AUTOSAR XML (schema 4-2-1)
package /MICROSAR/Dcm_swc
  4 x mode declaration group, all with category=EXPLICIT_ORDER:
    DcmControlDtcSetting: initial-mode=ENABLEDTCSETTING, on-transition-value=2
      mode ENABLEDTCSETTING: value=0
      mode DISABLEDTCSETTING: value=1
    DcmEcuReset: initial-mode=NONE, on-transition-value=7
      7 x mode:
        NONE: value=0
        HARD: value=1
        KEYONOFF: value=2
        SOFT: value=3
        JUMPTOBOOTLOADER: value=4
        JUMPTOSYSSUPPLIERBOOTLOADER: value=5
        EXECUTE: value=6
    DcmDiagnosticSessionControl: initial-mode=DEFAULT_SESSION, on-transition-value=255
      mode DEFAULT_SESSION: value=1
      mode EXTENDED_SESSION: value=3
    DcmCommunicationControl: initial-mode=DCM_ENABLE_RX_TX_NORM, on-transition-value=12
      12 x mode:
        DCM_ENABLE_RX_TX_NORM: value=0
        DCM_ENABLE_RX_DISABLE_TX_NORM: value=1
        DCM_DISABLE_RX_ENABLE_TX_NORM: value=2
        DCM_DISABLE_RX_TX_NORMAL: value=3
        DCM_ENABLE_RX_TX_NM: value=4
        DCM_ENABLE_RX_DISABLE_TX_NM: value=5
        DCM_DISABLE_RX_ENABLE_TX_NM: value=6
        DCM_DISABLE_RX_TX_NM: value=7
        DCM_ENABLE_RX_TX_NORM_NM: value=8
        DCM_ENABLE_RX_DISABLE_TX_NORM_NM: value=9
        DCM_DISABLE_RX_ENABLE_TX_NORM_NM: value=10
        DCM_DISABLE_RX_TX_NORM_NM: value=11
  data type mapping set DcmMappingSet  # Contains mapping for ModeDeclarationGroups which are provided by Dcm.
    mode-request-type-maps:
      implementation-data-type=Dcm_ControlDtcSettingType, mode-group=DcmControlDtcSetting
      implementation-data-type=Dcm_EcuResetType, mode-group=DcmEcuReset
      implementation-data-type=Dcm_DiagnosticSessionControlType, mode-group=DcmDiagnosticSessionControl
      implementation-data-type=Dcm_CommunicationModeType, mode-group=DcmCommunicationControl
package /MICROSAR/Dcm_swc/DataTypes
  22 x impl type:
    Dcm_ConfirmationStatusType: compu {0=DCM_RES_POS_OK, 1=DCM_RES_POS_NOT_OK, 2=DCM_RES_NEG_OK, 3=DCM_RES_NEG_NOT_OK}, range raw 0..3, implementation-data-type=uint8
    Dcm_OpStatusType: compu {0=DCM_INITIAL, 1=DCM_PENDING, 2=DCM_CANCEL, 3=DCM_FORCE_RCRRP_OK, 64=DCM_FORCE_RCRRP_NOT_OK}, range raw 0..64, implementation-data-type=uint8
    Dcm_NegativeResponseCodeType:
      compu {0=DCM_E_POSITIVERESPONSE, 16=DCM_E_GENERALREJECT, 17=DCM_E_SERVICENOTSUPPORTED, 18=DCM_E_SUBFUNCTIONNOTSUPPORTED, 19=DCM_E_INCORRECTMESSAGELENGTHORINVALIDFORMAT, 20=DCM_E_RESPONSETOOLONG, 33=DCM_E_BUSYREPEATREQUEST, 34=DCM_E_CONDITIONSNOTCORRECT, 36=DCM_E_REQUESTSEQUENCEERROR, 37=DCM_E_NORESPONSEFROMSUBNETCOMPONENT, 38=DCM_E_FAILUREPREVENTSEXECUTIONOFREQUESTEDACTION, 49=DCM_E_REQUESTOUTOFRANGE, 51=DCM_E_SECURITYACCESSDENIED, 53=DCM_E_INVALIDKEY, 54=DCM_E_EXCEEDNUMBEROFATTEMPTS, 55=DCM_E_REQUIREDTIMEDELAYNOTEXPIRED, 112=DCM_E_UPLOADDOWNLOADNOTACCEPTED, 113=DCM_E_TRANSFERDATASUSPENDED, 114=DCM_E_GENERALPROGRAMMINGFAILURE, 115=DCM_E_WRONGBLOCKSEQUENCECOUNTER, 120=DCM_E_REQUESTCORRECTLYRECEIVEDRESPONSEPENDING, 126=DCM_E_SUBFUNCTIONNOTSUPPORTEDINACTIVESESSION, 127=DCM_E_SERVICENOTSUPPORTEDINACTIVESESSION, 129=DCM_E_RPMTOOHIGH, 130=DCM_E_RPMTOOLOW, 131=DCM_E_ENGINEISRUNNING, 132=DCM_E_ENGINEISNOTRUNNING, 133=DCM_E_ENGINERUNTIMETOOLOW, 134=DCM_E_TEMPERATURETOOHIGH, 135=DCM_E_TEMPERATURETOOLOW, 136=DCM_E_VEHICLESPEEDTOOHIGH, 137=DCM_E_VEHICLESPEEDTOOLOW, 138=DCM_E_THROTTLE_PEDALTOOHIGH, 139=DCM_E_THROTTLE_PEDALTOOLOW, 140=DCM_E_TRANSMISSIONRANGENOTINNEUTRAL, 141=DCM_E_TRANSMISSIONRANGENOTINGEAR, 143=DCM_E_BRAKESWITCH_NOTCLOSED, 144=DCM_E_SHIFTERLEVERNOTINPARK, 145=DCM_E_TORQUECONVERTERCLUTCHLOCKED, 146=DCM_E_VOLTAGETOOHIGH, 147=DCM_E_VOLTAGETOOLOW, 240..249=DCM_E_VMSCNC_0..DCM_E_VMSCNC_9, 250=DCM_E_VMSCNC_A, 251=DCM_E_VMSCNC_B, 252=DCM_E_VMSCNC_C, 253=DCM_E_VMSCNC_D, 254=DCM_E_VMSCNC_E}
      range raw 0..254
      implementation-data-type=uint8
    Dcm_ProtocolType: compu {0=DCM_OBD_ON_CAN, 1=DCM_OBD_ON_FLEXRAY, 2=DCM_OBD_ON_IP, 3=DCM_UDS_ON_CAN, 4=DCM_UDS_ON_FLEXRAY, 5=DCM_UDS_ON_IP, 12=DCM_NO_ACTIVE_PROTOCOL, 240..254=DCM_SUPPLIER_1..DCM_SUPPLIER_15}, range raw 0..254, implementation-data-type=uint8
    Dcm_RequestKindType: compu {0=DCM_REQ_KIND_NONE, 1=DCM_REQ_KIND_EXTERNAL, 2=DCM_REQ_KIND_ROE}, range raw 0..2, implementation-data-type=uint8
    Dcm_SecLevelType: compu {0=DCM_SEC_LEV_LOCKED, 1=DCM_SEC_LEV_L1}, range raw 0..1, implementation-data-type=uint8
    Dcm_SesCtrlType: compu {1=DCM_DEFAULT_SESSION, 3=DCM_EXTENDED_DIAGNOSTIC_SESSION}, range raw 0..3, implementation-data-type=uint8
    Dcm_ControlDtcSettingType: compu {0=DCM_ENUM_ENABLEDTCSETTING, 1=DCM_ENUM_DISABLEDTCSETTING}, range raw 0..255, implementation-data-type=uint8
    Dcm_EcuResetType: compu {0=DCM_ENUM_NONE, 1=DCM_ENUM_HARD, 2=DCM_ENUM_KEYONOFF, 3=DCM_ENUM_SOFT, 4=DCM_ENUM_JUMPTOBOOTLOADER, 5=DCM_ENUM_JUMPTOSYSSUPPLIERBOOTLOADER, 6=DCM_ENUM_EXECUTE}, range raw 0..255, implementation-data-type=uint8
    Dcm_DiagnosticSessionControlType: compu {1=DCM_ENUM_DEFAULT_SESSION, 3=DCM_ENUM_EXTENDED_SESSION}, range raw 0..255, implementation-data-type=uint8
    Dcm_CommunicationModeType:
      compu {0=DCM_ENABLE_RX_TX_NORM, 1=DCM_ENABLE_RX_DISABLE_TX_NORM, 2=DCM_DISABLE_RX_ENABLE_TX_NORM, 3=DCM_DISABLE_RX_TX_NORMAL, 4=DCM_ENABLE_RX_TX_NM, 5=DCM_ENABLE_RX_DISABLE_TX_NM, 6=DCM_DISABLE_RX_ENABLE_TX_NM, 7=DCM_DISABLE_RX_TX_NM, 8=DCM_ENABLE_RX_TX_NORM_NM, 9=DCM_ENABLE_RX_DISABLE_TX_NORM_NM, 10=DCM_DISABLE_RX_ENABLE_TX_NORM_NM, 11=DCM_DISABLE_RX_TX_NORM_NM}
      range raw 0..255
      implementation-data-type=uint8
    Dcm_Data4ByteType: category=ARRAY, sw-calibration-access=READ-ONLY
      element Dcm_Data4ByteTypeElement: array-size=4, array-size-semantics=FIXED-SIZE, implementation-data-type=uint8
    Dcm_Data2ByteType: category=ARRAY, sw-calibration-access=READ-ONLY
      element Dcm_Data2ByteTypeElement: array-size=2, array-size-semantics=FIXED-SIZE, implementation-data-type=uint8
    Dcm_Data1ByteType: category=ARRAY, sw-calibration-access=READ-ONLY
      element Dcm_Data1ByteTypeElement: array-size=1, array-size-semantics=FIXED-SIZE, implementation-data-type=uint8
    Dcm_Data16ByteType: category=ARRAY, sw-calibration-access=READ-ONLY
      element Dcm_Data16ByteTypeElement: array-size=16, array-size-semantics=FIXED-SIZE, implementation-data-type=uint8
    Dcm_Data17ByteType: category=ARRAY, sw-calibration-access=READ-ONLY
      element Dcm_Data17ByteTypeElement: array-size=17, array-size-semantics=FIXED-SIZE, implementation-data-type=uint8
    Dcm_Data50ByteType: category=ARRAY, sw-calibration-access=READ-ONLY
      element Dcm_Data50ByteTypeElement: array-size=50, array-size-semantics=FIXED-SIZE, implementation-data-type=uint8
    Dcm_Data28ByteType: category=ARRAY, sw-calibration-access=READ-ONLY
      element Dcm_Data28ByteTypeElement: array-size=28, array-size-semantics=FIXED-SIZE, implementation-data-type=uint8
    Dcm_Data10ByteType: category=ARRAY, sw-calibration-access=READ-ONLY
      element Dcm_Data10ByteTypeElement: array-size=10, array-size-semantics=FIXED-SIZE, implementation-data-type=uint8
    Dcm_Data6ByteType: category=ARRAY, sw-calibration-access=READ-ONLY
      element Dcm_Data6ByteTypeElement: array-size=6, array-size-semantics=FIXED-SIZE, implementation-data-type=uint8
    Dcm_Data3ByteType: category=ARRAY, sw-calibration-access=READ-ONLY
      element Dcm_Data3ByteTypeElement: array-size=3, array-size-semantics=FIXED-SIZE, implementation-data-type=uint8
    Dcm_Data15ByteType: category=ARRAY, sw-calibration-access=READ-ONLY
      element Dcm_Data15ByteTypeElement: array-size=15, array-size-semantics=FIXED-SIZE, implementation-data-type=uint8
package /MICROSAR/Dcm_swc/Interfaces
  mode switch interface DcmControlDtcSetting: is-service=true, service-kind=DIAGNOSTIC-COMMUNICATION-MANAGER
    mode group DcmControlDtcSetting: type=DcmControlDtcSetting
  mode switch interface DcmEcuReset: is-service=true, service-kind=DIAGNOSTIC-COMMUNICATION-MANAGER
    mode group DcmEcuReset: type=DcmEcuReset
  mode switch interface DcmDiagnosticSessionControl: is-service=true, service-kind=DIAGNOSTIC-COMMUNICATION-MANAGER
    mode group DcmDiagnosticSessionControl: type=DcmDiagnosticSessionControl
  106 x client server interface, all with is-service=true, service-kind=DIAGNOSTIC-COMMUNICATION-MANAGER:
    DCMServices
      6 x operation:
        GetActiveProtocol: possible-error=E_OK
          arg ActiveProtocol: type=Dcm_ProtocolType, direction=OUT
        GetSesCtrlType: possible-error=E_OK
          arg SesCtrlType: type=Dcm_SesCtrlType, direction=OUT
        ResetToDefaultSession: possible-error=E_OK
        GetSecurityLevel: possible-error=E_OK
          arg SecLevel: type=Dcm_SecLevelType, direction=OUT
        SetActiveDiagnostic: possible-error=E_OK
          arg active: type=boolean, direction=IN
        GetRequestKind: possible-error=DCMServices/E_NOT_OK
          arg TesterSourceAddress: type=uint16, direction=IN
          arg RequestKind: type=Dcm_RequestKindType, direction=OUT
      error E_OK: error-code=0
      error E_NOT_OK: error-code=1
    SecurityAccess_UnlockedL1
      operation GetSeed: possible-error=[SecurityAccess_UnlockedL1/E_NOT_OK, SecurityAccess_UnlockedL1/DCM_E_PENDING]
        arg OpStatus: type=Dcm_OpStatusType, direction=IN
        arg Seed: type=Dcm_Data4ByteType, direction=OUT
        arg ErrorCode: type=Dcm_NegativeResponseCodeType, direction=OUT
      operation CompareKey: possible-error=[SecurityAccess_UnlockedL1/E_NOT_OK, SecurityAccess_UnlockedL1/DCM_E_PENDING, DCM_E_COMPARE_KEY_FAILED]
        arg Key: type=Dcm_Data4ByteType, direction=IN
        arg OpStatus: type=Dcm_OpStatusType, direction=IN
        arg ErrorCode: type=Dcm_NegativeResponseCodeType, direction=OUT
      error E_NOT_OK: error-code=1
      error DCM_E_PENDING: error-code=10
      error DCM_E_COMPARE_KEY_FAILED: error-code=11
    RoutineServices_HUT_self_check
      operation Start: possible-error=[RoutineServices_HUT_self_check/E_NOT_OK, RoutineServices_HUT_self_check/DCM_E_PENDING, DCM_E_FORCE_RCRRP]
        arg OpStatus: type=Dcm_OpStatusType, direction=IN
        arg ErrorCode: type=Dcm_NegativeResponseCodeType, direction=OUT
      operation Stop: possible-error=[RoutineServices_HUT_self_check/E_NOT_OK, RoutineServices_HUT_self_check/DCM_E_PENDING, DCM_E_FORCE_RCRRP]
        arg OpStatus: type=Dcm_OpStatusType, direction=IN
        arg ErrorCode: type=Dcm_NegativeResponseCodeType, direction=OUT
      operation RequestResults: possible-error=[RoutineServices_HUT_self_check/E_NOT_OK, RoutineServices_HUT_self_check/DCM_E_PENDING, DCM_E_FORCE_RCRRP]
        arg OpStatus: type=Dcm_OpStatusType, direction=IN
        arg ErrorCode: type=Dcm_NegativeResponseCodeType, direction=OUT
      error E_NOT_OK: error-code=1
      error DCM_E_PENDING: error-code=10
      error DCM_E_FORCE_RCRRP: error-code=12
    DataServices_Vehicle_Speed_D001_Vehicle_Speed
      operation ReadData: possible-error=[DataServices_Vehicle_Speed_D001_Vehicle_Speed/E_NOT_OK, DataServices_Vehicle_Speed_D001_Vehicle_Speed/DCM_E_PENDING]
        arg OpStatus: type=Dcm_OpStatusType, direction=IN
        arg Data: type=Dcm_Data2ByteType, direction=OUT
      operation ConditionCheckRead: possible-error=[DataServices_Vehicle_Speed_D001_Vehicle_Speed/E_NOT_OK, DataServices_Vehicle_Speed_D001_Vehicle_Speed/DCM_E_PENDING]
        arg OpStatus: type=Dcm_OpStatusType, direction=IN
        arg ErrorCode: type=Dcm_NegativeResponseCodeType, direction=OUT
      error E_NOT_OK: error-code=1
      error DCM_E_PENDING: error-code=10
    DataServices_Telematics_Module_Status_E01A_Telematics_Module_Status
      operation ReadData: possible-error=[DataServices_Telematics_Module_Status_E01A_Telematics_Module_Status/E_NOT_OK, DataServices_Telematics_Module_Status_E01A_Telematics_Module_Status/DCM_E_PENDING]
        arg OpStatus: type=Dcm_OpStatusType, direction=IN
        arg Data: type=Dcm_Data1ByteType, direction=OUT
      operation ConditionCheckRead: possible-error=[DataServices_Telematics_Module_Status_E01A_Telematics_Module_Status/E_NOT_OK, DataServices_Telematics_Module_Status_E01A_Telematics_Module_Status/DCM_E_PENDING]
        arg OpStatus: type=Dcm_OpStatusType, direction=IN
        arg ErrorCode: type=Dcm_NegativeResponseCodeType, direction=OUT
      error E_NOT_OK: error-code=1
      error DCM_E_PENDING: error-code=10
    DataServices_Wi_Fi_Module_Status_E013_Wi_Fi_Module_Status
      operation ReadData: possible-error=[DataServices_Wi_Fi_Module_Status_E013_Wi_Fi_Module_Status/E_NOT_OK, DataServices_Wi_Fi_Module_Status_E013_Wi_Fi_Module_Status/DCM_E_PENDING]
        arg OpStatus: type=Dcm_OpStatusType, direction=IN
        arg Data: type=Dcm_Data1ByteType, direction=OUT
      operation ConditionCheckRead: possible-error=[DataServices_Wi_Fi_Module_Status_E013_Wi_Fi_Module_Status/E_NOT_OK, DataServices_Wi_Fi_Module_Status_E013_Wi_Fi_Module_Status/DCM_E_PENDING]
        arg OpStatus: type=Dcm_OpStatusType, direction=IN
        arg ErrorCode: type=Dcm_NegativeResponseCodeType, direction=OUT
      error E_NOT_OK: error-code=1
      error DCM_E_PENDING: error-code=10
    DataServices_BT_firmware_version_E009_BT_firmware_version
      operation ReadData: possible-error=[DataServices_BT_firmware_version_E009_BT_firmware_version/E_NOT_OK, DataServices_BT_firmware_version_E009_BT_firmware_version/DCM_E_PENDING]
        arg OpStatus: type=Dcm_OpStatusType, direction=IN
        arg Data: type=Dcm_Data16ByteType, direction=OUT
      operation ConditionCheckRead: possible-error=[DataServices_BT_firmware_version_E009_BT_firmware_version/E_NOT_OK, DataServices_BT_firmware_version_E009_BT_firmware_version/DCM_E_PENDING]
        arg OpStatus: type=Dcm_OpStatusType, direction=IN
        arg ErrorCode: type=Dcm_NegativeResponseCodeType, direction=OUT
      error E_NOT_OK: error-code=1
      error DCM_E_PENDING: error-code=10
    DataServices_BT_active_profile_list_E008_BT_active_profile_list
      operation ReadData: possible-error=[DataServices_BT_active_profile_list_E008_BT_active_profile_list/E_NOT_OK, DataServices_BT_active_profile_list_E008_BT_active_profile_list/DCM_E_PENDING]
        arg OpStatus: type=Dcm_OpStatusType, direction=IN
        arg Data: type=Dcm_Data1ByteType, direction=OUT
      operation ConditionCheckRead: possible-error=[DataServices_BT_active_profile_list_E008_BT_active_profile_list/E_NOT_OK, DataServices_BT_active_profile_list_E008_BT_active_profile_list/DCM_E_PENDING]
        arg OpStatus: type=Dcm_OpStatusType, direction=IN
        arg ErrorCode: type=Dcm_NegativeResponseCodeType, direction=OUT
      error E_NOT_OK: error-code=1
      error DCM_E_PENDING: error-code=10
    DataServices_Vehicle_Identification_Number_F190_VIN
      operation ReadData: possible-error=[DataServices_Vehicle_Identification_Number_F190_VIN/E_NOT_OK, DataServices_Vehicle_Identification_Number_F190_VIN/DCM_E_PENDING]
        arg OpStatus: type=Dcm_OpStatusType, direction=IN
        arg Data: type=Dcm_Data17ByteType, direction=OUT
      operation ConditionCheckRead: possible-error=[DataServices_Vehicle_Identification_Number_F190_VIN/E_NOT_OK, DataServices_Vehicle_Identification_Number_F190_VIN/DCM_E_PENDING]
        arg OpStatus: type=Dcm_OpStatusType, direction=IN
        arg ErrorCode: type=Dcm_NegativeResponseCodeType, direction=OUT
      operation WriteData: possible-error=[DataServices_Vehicle_Identification_Number_F190_VIN/E_NOT_OK, DataServices_Vehicle_Identification_Number_F190_VIN/DCM_E_PENDING]
        arg Data: type=Dcm_Data17ByteType, direction=IN
        arg OpStatus: type=Dcm_OpStatusType, direction=IN
        arg ErrorCode: type=Dcm_NegativeResponseCodeType, direction=OUT
      error E_NOT_OK: error-code=1
      error DCM_E_PENDING: error-code=10
    DataServices_AME_Read_SW_and_HW_Version_FD04_CombinedDataElement
      operation ReadData: possible-error=[DataServices_AME_Read_SW_and_HW_Version_FD04_CombinedDataElement/E_NOT_OK, DataServices_AME_Read_SW_and_HW_Version_FD04_CombinedDataElement/DCM_E_PENDING]
        arg OpStatus: type=Dcm_OpStatusType, direction=IN
        arg Data: type=Dcm_Data50ByteType, direction=OUT
      operation ReadDataLength: possible-error=[DataServices_AME_Read_SW_and_HW_Version_FD04_CombinedDataElement/E_NOT_OK, DataServices_AME_Read_SW_and_HW_Version_FD04_CombinedDataElement/DCM_E_PENDING]
        arg OpStatus: type=Dcm_OpStatusType, direction=IN
        arg DataLength: type=uint16, direction=OUT
      operation ConditionCheckRead: possible-error=[DataServices_AME_Read_SW_and_HW_Version_FD04_CombinedDataElement/E_NOT_OK, DataServices_AME_Read_SW_and_HW_Version_FD04_CombinedDataElement/DCM_E_PENDING]
        arg OpStatus: type=Dcm_OpStatusType, direction=IN
        arg ErrorCode: type=Dcm_NegativeResponseCodeType, direction=OUT
      error E_NOT_OK: error-code=1
      error DCM_E_PENDING: error-code=10
    DataServices_AME_Skip_welcome_confirm_FD20_Reserved_Byte
      operation WriteData: possible-error=[DataServices_AME_Skip_welcome_confirm_FD20_Reserved_Byte/E_NOT_OK, DataServices_AME_Skip_welcome_confirm_FD20_Reserved_Byte/DCM_E_PENDING]
        arg Data: type=Dcm_Data1ByteType, direction=IN
        arg OpStatus: type=Dcm_OpStatusType, direction=IN
        arg ErrorCode: type=Dcm_NegativeResponseCodeType, direction=OUT
      error E_NOT_OK: error-code=1
      error DCM_E_PENDING: error-code=10
    DataServices_Select_Speaker_Test_Tone_FD34_Select_tone
      operation WriteData: possible-error=[DataServices_Select_Speaker_Test_Tone_FD34_Select_tone/E_NOT_OK, DataServices_Select_Speaker_Test_Tone_FD34_Select_tone/DCM_E_PENDING]
        arg Data: type=Dcm_Data1ByteType, direction=IN
        arg OpStatus: type=Dcm_OpStatusType, direction=IN
        arg ErrorCode: type=Dcm_NegativeResponseCodeType, direction=OUT
      error E_NOT_OK: error-code=1
      error DCM_E_PENDING: error-code=10
    DataServices_AME_Read_GPS_Info_FD72_Number_of_used_satellite
      operation ReadData: possible-error=[DataServices_AME_Read_GPS_Info_FD72_Number_of_used_satellite/E_NOT_OK, DataServices_AME_Read_GPS_Info_FD72_Number_of_used_satellite/DCM_E_PENDING]
        arg OpStatus: type=Dcm_OpStatusType, direction=IN
        arg Data: type=Dcm_Data1ByteType, direction=OUT
      operation ConditionCheckRead: possible-error=[DataServices_AME_Read_GPS_Info_FD72_Number_of_used_satellite/E_NOT_OK, DataServices_AME_Read_GPS_Info_FD72_Number_of_used_satellite/DCM_E_PENDING]
        arg OpStatus: type=Dcm_OpStatusType, direction=IN
        arg ErrorCode: type=Dcm_NegativeResponseCodeType, direction=OUT
      error E_NOT_OK: error-code=1
      error DCM_E_PENDING: error-code=10
    DataServices_AME_Read_GPS_Info_FD72_Number_of_visible_staellite
      operation ReadData: possible-error=[DataServices_AME_Read_GPS_Info_FD72_Number_of_visible_staellite/E_NOT_OK, DataServices_AME_Read_GPS_Info_FD72_Number_of_visible_staellite/DCM_E_PENDING]
        arg OpStatus: type=Dcm_OpStatusType, direction=IN
        arg Data: type=Dcm_Data1ByteType, direction=OUT
      operation ConditionCheckRead: possible-error=[DataServices_AME_Read_GPS_Info_FD72_Number_of_visible_staellite/E_NOT_OK, DataServices_AME_Read_GPS_Info_FD72_Number_of_visible_staellite/DCM_E_PENDING]
        arg OpStatus: type=Dcm_OpStatusType, direction=IN
        arg ErrorCode: type=Dcm_NegativeResponseCodeType, direction=OUT
      error E_NOT_OK: error-code=1
      error DCM_E_PENDING: error-code=10
    DataServices_AME_Read_GPS_Info_FD72_Number_of_fix
      operation ReadData: possible-error=[DataServices_AME_Read_GPS_Info_FD72_Number_of_fix/E_NOT_OK, DataServices_AME_Read_GPS_Info_FD72_Number_of_fix/DCM_E_PENDING]
        arg OpStatus: type=Dcm_OpStatusType, direction=IN
        arg Data: type=Dcm_Data1ByteType, direction=OUT
      operation ConditionCheckRead: possible-error=[DataServices_AME_Read_GPS_Info_FD72_Number_of_fix/E_NOT_OK, DataServices_AME_Read_GPS_Info_FD72_Number_of_fix/DCM_E_PENDING]
        arg OpStatus: type=Dcm_OpStatusType, direction=IN
        arg ErrorCode: type=Dcm_NegativeResponseCodeType, direction=OUT
      error E_NOT_OK: error-code=1
      error DCM_E_PENDING: error-code=10
    DataServices_AME_Set_AM_Frequency_FD52_AM_Frequency
      operation WriteData: possible-error=[DataServices_AME_Set_AM_Frequency_FD52_AM_Frequency/E_NOT_OK, DataServices_AME_Set_AM_Frequency_FD52_AM_Frequency/DCM_E_PENDING]
        arg Data: type=Dcm_Data2ByteType, direction=IN
        arg OpStatus: type=Dcm_OpStatusType, direction=IN
        arg ErrorCode: type=Dcm_NegativeResponseCodeType, direction=OUT
      error E_NOT_OK: error-code=1
      error DCM_E_PENDING: error-code=10
    DataServices_AME_Power_Control_FD01_Power_Control
      operation WriteData: possible-error=[DataServices_AME_Power_Control_FD01_Power_Control/E_NOT_OK, DataServices_AME_Power_Control_FD01_Power_Control/DCM_E_PENDING]
        arg Data: type=Dcm_Data1ByteType, direction=IN
        arg OpStatus: type=Dcm_OpStatusType, direction=IN
        arg ErrorCode: type=Dcm_NegativeResponseCodeType, direction=OUT
      error E_NOT_OK: error-code=1
      error DCM_E_PENDING: error-code=10
    DataServices_AME_Set_Mute_Control_FD31_Set_Mute_Control
      operation WriteData: possible-error=[DataServices_AME_Set_Mute_Control_FD31_Set_Mute_Control/E_NOT_OK, DataServices_AME_Set_Mute_Control_FD31_Set_Mute_Control/DCM_E_PENDING]
        arg Data: type=Dcm_Data1ByteType, direction=IN
        arg OpStatus: type=Dcm_OpStatusType, direction=IN
        arg ErrorCode: type=Dcm_NegativeResponseCodeType, direction=OUT
      error E_NOT_OK: error-code=1
      error DCM_E_PENDING: error-code=10
    DataServices_AME_Set_Volume_FD30_Set_Volume
      operation WriteData: possible-error=[DataServices_AME_Set_Volume_FD30_Set_Volume/E_NOT_OK, DataServices_AME_Set_Volume_FD30_Set_Volume/DCM_E_PENDING]
        arg Data: type=Dcm_Data1ByteType, direction=IN
        arg OpStatus: type=Dcm_OpStatusType, direction=IN
        arg ErrorCode: type=Dcm_NegativeResponseCodeType, direction=OUT
      error E_NOT_OK: error-code=1
      error DCM_E_PENDING: error-code=10
    DataServices_Audio_jack_status_E00A_Audio_jack_status
      operation ReadData: possible-error=[DataServices_Audio_jack_status_E00A_Audio_jack_status/E_NOT_OK, DataServices_Audio_jack_status_E00A_Audio_jack_status/DCM_E_PENDING]
        arg OpStatus: type=Dcm_OpStatusType, direction=IN
        arg Data: type=Dcm_Data1ByteType, direction=OUT
      operation ConditionCheckRead: possible-error=[DataServices_Audio_jack_status_E00A_Audio_jack_status/E_NOT_OK, DataServices_Audio_jack_status_E00A_Audio_jack_status/DCM_E_PENDING]
        arg OpStatus: type=Dcm_OpStatusType, direction=IN
        arg ErrorCode: type=Dcm_NegativeResponseCodeType, direction=OUT
      error E_NOT_OK: error-code=1
      error DCM_E_PENDING: error-code=10
    DataServices_AME_ReadGPSSNR_FD73_GPSSNR
      operation ReadData: possible-error=[DataServices_AME_ReadGPSSNR_FD73_GPSSNR/E_NOT_OK, DataServices_AME_ReadGPSSNR_FD73_GPSSNR/DCM_E_PENDING]
        arg OpStatus: type=Dcm_OpStatusType, direction=IN
        arg Data: type=Dcm_Data1ByteType, direction=OUT
      operation ConditionCheckRead: possible-error=[DataServices_AME_ReadGPSSNR_FD73_GPSSNR/E_NOT_OK, DataServices_AME_ReadGPSSNR_FD73_GPSSNR/DCM_E_PENDING]
        arg OpStatus: type=Dcm_OpStatusType, direction=IN
        arg ErrorCode: type=Dcm_NegativeResponseCodeType, direction=OUT
      error E_NOT_OK: error-code=1
      error DCM_E_PENDING: error-code=10
    DataServices_Support_FM_frequency_Min_E00F_Support_FM_frequency_Min
      operation ReadData: possible-error=[DataServices_Support_FM_frequency_Min_E00F_Support_FM_frequency_Min/E_NOT_OK, DataServices_Support_FM_frequency_Min_E00F_Support_FM_frequency_Min/DCM_E_PENDING]
        arg OpStatus: type=Dcm_OpStatusType, direction=IN
        arg Data: type=Dcm_Data4ByteType, direction=OUT
      operation ConditionCheckRead: possible-error=[DataServices_Support_FM_frequency_Min_E00F_Support_FM_frequency_Min/E_NOT_OK, DataServices_Support_FM_frequency_Min_E00F_Support_FM_frequency_Min/DCM_E_PENDING]
        arg OpStatus: type=Dcm_OpStatusType, direction=IN
        arg ErrorCode: type=Dcm_NegativeResponseCodeType, direction=OUT
      error E_NOT_OK: error-code=1
      error DCM_E_PENDING: error-code=10
    DataServices_Support_FM_frequency_Max_E010_Support_FM_frequency_Max
      operation ReadData: possible-error=[DataServices_Support_FM_frequency_Max_E010_Support_FM_frequency_Max/E_NOT_OK, DataServices_Support_FM_frequency_Max_E010_Support_FM_frequency_Max/DCM_E_PENDING]
        arg OpStatus: type=Dcm_OpStatusType, direction=IN
        arg Data: type=Dcm_Data4ByteType, direction=OUT
      operation ConditionCheckRead: possible-error=[DataServices_Support_FM_frequency_Max_E010_Support_FM_frequency_Max/E_NOT_OK, DataServices_Support_FM_frequency_Max_E010_Support_FM_frequency_Max/DCM_E_PENDING]
        arg OpStatus: type=Dcm_OpStatusType, direction=IN
        arg ErrorCode: type=Dcm_NegativeResponseCodeType, direction=OUT
      error E_NOT_OK: error-code=1
      error DCM_E_PENDING: error-code=10
    DataServices_Number_of_installed_cameras_E001_Number_of_installed_cameras
      operation ReadData: possible-error=[DataServices_Number_of_installed_cameras_E001_Number_of_installed_cameras/E_NOT_OK, DataServices_Number_of_installed_cameras_E001_Number_of_installed_cameras/DCM_E_PENDING]
        arg OpStatus: type=Dcm_OpStatusType, direction=IN
        arg Data: type=Dcm_Data1ByteType, direction=OUT
      operation ConditionCheckRead: possible-error=[DataServices_Number_of_installed_cameras_E001_Number_of_installed_cameras/E_NOT_OK, DataServices_Number_of_installed_cameras_E001_Number_of_installed_cameras/DCM_E_PENDING]
        arg OpStatus: type=Dcm_OpStatusType, direction=IN
        arg ErrorCode: type=Dcm_NegativeResponseCodeType, direction=OUT
      error E_NOT_OK: error-code=1
      error DCM_E_PENDING: error-code=10
    DataServices_AME_Write_harman_manufactory_part_number_FD07_Harman_Manufactory_Part_Number
      operation WriteData: possible-error=[DataServices_AME_Write_harman_manufactory_part_number_FD07_Harman_Manufactory_Part_Number/E_NOT_OK, DataServices_AME_Write_harman_manufactory_part_number_FD07_Harman_Manufactory_Part_Number/DCM_E_PENDING]
        arg Data: type=Dcm_Data28ByteType, direction=IN
        arg OpStatus: type=Dcm_OpStatusType, direction=IN
        arg ErrorCode: type=Dcm_NegativeResponseCodeType, direction=OUT
      error E_NOT_OK: error-code=1
      error DCM_E_PENDING: error-code=10
    DataServices_AME_Read_system_temperature_FD13_CombinedDataElement
      operation ReadData: possible-error=[DataServices_AME_Read_system_temperature_FD13_CombinedDataElement/E_NOT_OK, DataServices_AME_Read_system_temperature_FD13_CombinedDataElement/DCM_E_PENDING]
        arg OpStatus: type=Dcm_OpStatusType, direction=IN
        arg Data: type=Dcm_Data2ByteType, direction=OUT
      operation ConditionCheckRead: possible-error=[DataServices_AME_Read_system_temperature_FD13_CombinedDataElement/E_NOT_OK, DataServices_AME_Read_system_temperature_FD13_CombinedDataElement/DCM_E_PENDING]
        arg OpStatus: type=Dcm_OpStatusType, direction=IN
        arg ErrorCode: type=Dcm_NegativeResponseCodeType, direction=OUT
      error E_NOT_OK: error-code=1
      error DCM_E_PENDING: error-code=10
    DataServices_AME_Set_FAN_speed_FD12_FAN_Speed
      operation WriteData: possible-error=[DataServices_AME_Set_FAN_speed_FD12_FAN_Speed/E_NOT_OK, DataServices_AME_Set_FAN_speed_FD12_FAN_Speed/DCM_E_PENDING]
        arg Data: type=Dcm_Data1ByteType, direction=IN
        arg OpStatus: type=Dcm_OpStatusType, direction=IN
        arg ErrorCode: type=Dcm_NegativeResponseCodeType, direction=OUT
      error E_NOT_OK: error-code=1
      error DCM_E_PENDING: error-code=10
    DataServices_System_Supplier_Identifier_F18A_System_Supplier_Identifier
      operation ReadData: possible-error=[DataServices_System_Supplier_Identifier_F18A_System_Supplier_Identifier/E_NOT_OK, DataServices_System_Supplier_Identifier_F18A_System_Supplier_Identifier/DCM_E_PENDING]
        arg OpStatus: type=Dcm_OpStatusType, direction=IN
        arg Data: type=Dcm_Data10ByteType, direction=OUT
      operation ConditionCheckRead: possible-error=[DataServices_System_Supplier_Identifier_F18A_System_Supplier_Identifier/E_NOT_OK, DataServices_System_Supplier_Identifier_F18A_System_Supplier_Identifier/DCM_E_PENDING]
        arg OpStatus: type=Dcm_OpStatusType, direction=IN
        arg ErrorCode: type=Dcm_NegativeResponseCodeType, direction=OUT
      error E_NOT_OK: error-code=1
      error DCM_E_PENDING: error-code=10
    DataServices_AME_Route_MIC_To_Internal_Speaker_FD36_Control
      operation WriteData: possible-error=[DataServices_AME_Route_MIC_To_Internal_Speaker_FD36_Control/E_NOT_OK, DataServices_AME_Route_MIC_To_Internal_Speaker_FD36_Control/DCM_E_PENDING]
        arg Data: type=Dcm_Data1ByteType, direction=IN
        arg OpStatus: type=Dcm_OpStatusType, direction=IN
        arg ErrorCode: type=Dcm_NegativeResponseCodeType, direction=OUT
      error E_NOT_OK: error-code=1
      error DCM_E_PENDING: error-code=10
    DataServices_AME_Route_MIC_To_Internal_Speaker_FD36_Mic
      operation WriteData: possible-error=[DataServices_AME_Route_MIC_To_Internal_Speaker_FD36_Mic/E_NOT_OK, DataServices_AME_Route_MIC_To_Internal_Speaker_FD36_Mic/DCM_E_PENDING]
        arg Data: type=Dcm_Data1ByteType, direction=IN
        arg OpStatus: type=Dcm_OpStatusType, direction=IN
        arg ErrorCode: type=Dcm_NegativeResponseCodeType, direction=OUT
      error E_NOT_OK: error-code=1
      error DCM_E_PENDING: error-code=10
    DataServices_Currently_connected_USB_Type_E00C_Currently_connected_USB_Type
      operation ReadData: possible-error=[DataServices_Currently_connected_USB_Type_E00C_Currently_connected_USB_Type/E_NOT_OK, DataServices_Currently_connected_USB_Type_E00C_Currently_connected_USB_Type/DCM_E_PENDING]
        arg OpStatus: type=Dcm_OpStatusType, direction=IN
        arg Data: type=Dcm_Data1ByteType, direction=OUT
      operation ConditionCheckRead: possible-error=[DataServices_Currently_connected_USB_Type_E00C_Currently_connected_USB_Type/E_NOT_OK, DataServices_Currently_connected_USB_Type_E00C_Currently_connected_USB_Type/DCM_E_PENDING]
        arg OpStatus: type=Dcm_OpStatusType, direction=IN
        arg ErrorCode: type=Dcm_NegativeResponseCodeType, direction=OUT
      error E_NOT_OK: error-code=1
      error DCM_E_PENDING: error-code=10
    DataServices_Bluetooth_Status_E006_Bluetooth_Status
      operation ReadData: possible-error=[DataServices_Bluetooth_Status_E006_Bluetooth_Status/E_NOT_OK, DataServices_Bluetooth_Status_E006_Bluetooth_Status/DCM_E_PENDING]
        arg OpStatus: type=Dcm_OpStatusType, direction=IN
        arg Data: type=Dcm_Data1ByteType, direction=OUT
      operation ConditionCheckRead: possible-error=[DataServices_Bluetooth_Status_E006_Bluetooth_Status/E_NOT_OK, DataServices_Bluetooth_Status_E006_Bluetooth_Status/DCM_E_PENDING]
        arg OpStatus: type=Dcm_OpStatusType, direction=IN
        arg ErrorCode: type=Dcm_NegativeResponseCodeType, direction=OUT
      error E_NOT_OK: error-code=1
      error DCM_E_PENDING: error-code=10
    DataServices_AME_Select_Audio_Buffer_Channel_Output_FD39_SelectAudioBufferChannelOutput
      operation WriteData: possible-error=[DataServices_AME_Select_Audio_Buffer_Channel_Output_FD39_SelectAudioBufferChannelOutput/E_NOT_OK, DataServices_AME_Select_Audio_Buffer_Channel_Output_FD39_SelectAudioBufferChannelOutput/DCM_E_PENDING]
        arg Data: type=Dcm_Data1ByteType, direction=IN
        arg OpStatus: type=Dcm_OpStatusType, direction=IN
        arg ErrorCode: type=Dcm_NegativeResponseCodeType, direction=OUT
      error E_NOT_OK: error-code=1
      error DCM_E_PENDING: error-code=10
    DataServices_AME_Route_Video_To_HMI_FD37_Route_Vedio_To_HMI
      operation WriteData: possible-error=[DataServices_AME_Route_Video_To_HMI_FD37_Route_Vedio_To_HMI/E_NOT_OK, DataServices_AME_Route_Video_To_HMI_FD37_Route_Vedio_To_HMI/DCM_E_PENDING]
        arg Data: type=Dcm_Data1ByteType, direction=IN
        arg OpStatus: type=Dcm_OpStatusType, direction=IN
        arg ErrorCode: type=Dcm_NegativeResponseCodeType, direction=OUT
      error E_NOT_OK: error-code=1
      error DCM_E_PENDING: error-code=10
    DataServices_FM_signal_Strength_E012_FM_signal_Strength
      operation ReadData: possible-error=[DataServices_FM_signal_Strength_E012_FM_signal_Strength/E_NOT_OK, DataServices_FM_signal_Strength_E012_FM_signal_Strength/DCM_E_PENDING]
        arg OpStatus: type=Dcm_OpStatusType, direction=IN
        arg Data: type=Dcm_Data1ByteType, direction=OUT
      operation ConditionCheckRead: possible-error=[DataServices_FM_signal_Strength_E012_FM_signal_Strength/E_NOT_OK, DataServices_FM_signal_Strength_E012_FM_signal_Strength/DCM_E_PENDING]
        arg OpStatus: type=Dcm_OpStatusType, direction=IN
        arg ErrorCode: type=Dcm_NegativeResponseCodeType, direction=OUT
      error E_NOT_OK: error-code=1
      error DCM_E_PENDING: error-code=10
    DataServices_AME_Switch_Source_FD40_SelectAudioBufferChannelOutput
      operation WriteData: possible-error=[DataServices_AME_Switch_Source_FD40_SelectAudioBufferChannelOutput/E_NOT_OK, DataServices_AME_Switch_Source_FD40_SelectAudioBufferChannelOutput/DCM_E_PENDING]
        arg Data: type=Dcm_Data1ByteType, direction=IN
        arg OpStatus: type=Dcm_OpStatusType, direction=IN
        arg ErrorCode: type=Dcm_NegativeResponseCodeType, direction=OUT
      error E_NOT_OK: error-code=1
      error DCM_E_PENDING: error-code=10
    DataServices_AME_Mirror_Link_connection_FD6D_Mirror_Link_connection
      operation WriteData: possible-error=[DataServices_AME_Mirror_Link_connection_FD6D_Mirror_Link_connection/E_NOT_OK, DataServices_AME_Mirror_Link_connection_FD6D_Mirror_Link_connection/DCM_E_PENDING]
        arg Data: type=Dcm_Data1ByteType, direction=IN
        arg OpStatus: type=Dcm_OpStatusType, direction=IN
        arg ErrorCode: type=Dcm_NegativeResponseCodeType, direction=OUT
      error E_NOT_OK: error-code=1
      error DCM_E_PENDING: error-code=10
    DataServices_AME_BT_Auto_Pairing_FD63_BT_Chip
      operation WriteData: possible-error=[DataServices_AME_BT_Auto_Pairing_FD63_BT_Chip/E_NOT_OK, DataServices_AME_BT_Auto_Pairing_FD63_BT_Chip/DCM_E_PENDING]
        arg Data: type=Dcm_Data1ByteType, direction=IN
        arg OpStatus: type=Dcm_OpStatusType, direction=IN
        arg ErrorCode: type=Dcm_NegativeResponseCodeType, direction=OUT
      error E_NOT_OK: error-code=1
      error DCM_E_PENDING: error-code=10
    DataServices_AME_BT_Auto_Pairing_FD63_BT_MAC_Address
      operation WriteData: possible-error=[DataServices_AME_BT_Auto_Pairing_FD63_BT_MAC_Address/E_NOT_OK, DataServices_AME_BT_Auto_Pairing_FD63_BT_MAC_Address/DCM_E_PENDING]
        arg Data: type=Dcm_Data6ByteType, direction=IN
        arg OpStatus: type=Dcm_OpStatusType, direction=IN
        arg ErrorCode: type=Dcm_NegativeResponseCodeType, direction=OUT
      error E_NOT_OK: error-code=1
      error DCM_E_PENDING: error-code=10
    DataServices_Odometer_D004_Odometer
      operation ReadData: possible-error=[DataServices_Odometer_D004_Odometer/E_NOT_OK, DataServices_Odometer_D004_Odometer/DCM_E_PENDING]
        arg OpStatus: type=Dcm_OpStatusType, direction=IN
        arg Data: type=Dcm_Data3ByteType, direction=OUT
      operation ConditionCheckRead: possible-error=[DataServices_Odometer_D004_Odometer/E_NOT_OK, DataServices_Odometer_D004_Odometer/DCM_E_PENDING]
        arg OpStatus: type=Dcm_OpStatusType, direction=IN
        arg ErrorCode: type=Dcm_NegativeResponseCodeType, direction=OUT
      error E_NOT_OK: error-code=1
      error DCM_E_PENDING: error-code=10
    DataServices_Wi_Fi_Module_Hardware_Part_Number_E015_Wi_Fi_Module_Hardware_Part_Number
      operation ReadData: possible-error=[DataServices_Wi_Fi_Module_Hardware_Part_Number_E015_Wi_Fi_Module_Hardware_Part_Number/E_NOT_OK, DataServices_Wi_Fi_Module_Hardware_Part_Number_E015_Wi_Fi_Module_Hardware_Part_Number/DCM_E_PENDING]
        arg OpStatus: type=Dcm_OpStatusType, direction=IN
        arg Data: type=Dcm_Data16ByteType, direction=OUT
      operation ConditionCheckRead: possible-error=[DataServices_Wi_Fi_Module_Hardware_Part_Number_E015_Wi_Fi_Module_Hardware_Part_Number/E_NOT_OK, DataServices_Wi_Fi_Module_Hardware_Part_Number_E015_Wi_Fi_Module_Hardware_Part_Number/DCM_E_PENDING]
        arg OpStatus: type=Dcm_OpStatusType, direction=IN
        arg ErrorCode: type=Dcm_NegativeResponseCodeType, direction=OUT
      error E_NOT_OK: error-code=1
      error DCM_E_PENDING: error-code=10
    DataServices_AME_Display_Color_Bar_Control_FD38_Display_Color_Bar_Control
      operation WriteData: possible-error=[DataServices_AME_Display_Color_Bar_Control_FD38_Display_Color_Bar_Control/E_NOT_OK, DataServices_AME_Display_Color_Bar_Control_FD38_Display_Color_Bar_Control/DCM_E_PENDING]
        arg Data: type=Dcm_Data1ByteType, direction=IN
        arg OpStatus: type=Dcm_OpStatusType, direction=IN
        arg ErrorCode: type=Dcm_NegativeResponseCodeType, direction=OUT
      error E_NOT_OK: error-code=1
      error DCM_E_PENDING: error-code=10
    DataServices_AME_Enter_NAV_Demo_Mode_FD70_Demo_Mode
      operation WriteData: possible-error=[DataServices_AME_Enter_NAV_Demo_Mode_FD70_Demo_Mode/E_NOT_OK, DataServices_AME_Enter_NAV_Demo_Mode_FD70_Demo_Mode/DCM_E_PENDING]
        arg Data: type=Dcm_Data1ByteType, direction=IN
        arg OpStatus: type=Dcm_OpStatusType, direction=IN
        arg ErrorCode: type=Dcm_NegativeResponseCodeType, direction=OUT
      error E_NOT_OK: error-code=1
      error DCM_E_PENDING: error-code=10
    DataServices_Support_AM_frequency_Min_E00D_Support_AM_frequency_Min
      operation ReadData: possible-error=[DataServices_Support_AM_frequency_Min_E00D_Support_AM_frequency_Min/E_NOT_OK, DataServices_Support_AM_frequency_Min_E00D_Support_AM_frequency_Min/DCM_E_PENDING]
        arg OpStatus: type=Dcm_OpStatusType, direction=IN
        arg Data: type=Dcm_Data4ByteType, direction=OUT
      operation ConditionCheckRead: possible-error=[DataServices_Support_AM_frequency_Min_E00D_Support_AM_frequency_Min/E_NOT_OK, DataServices_Support_AM_frequency_Min_E00D_Support_AM_frequency_Min/DCM_E_PENDING]
        arg OpStatus: type=Dcm_OpStatusType, direction=IN
        arg ErrorCode: type=Dcm_NegativeResponseCodeType, direction=OUT
      error E_NOT_OK: error-code=1
      error DCM_E_PENDING: error-code=10
    DataServices_Bluetooth_Current_Discoverability_modes_E005_Bluetooth_Current_Discoverability_modes
      operation ReadData: possible-error=[DataServices_Bluetooth_Current_Discoverability_modes_E005_Bluetooth_Current_Discoverability_modes/E_NOT_OK, DataServices_Bluetooth_Current_Discoverability_modes_E005_Bluetooth_Current_Discoverability_modes/DCM_E_PENDING]
        arg OpStatus: type=Dcm_OpStatusType, direction=IN
        arg Data: type=Dcm_Data1ByteType, direction=OUT
      operation ConditionCheckRead: possible-error=[DataServices_Bluetooth_Current_Discoverability_modes_E005_Bluetooth_Current_Discoverability_modes/E_NOT_OK, DataServices_Bluetooth_Current_Discoverability_modes_E005_Bluetooth_Current_Discoverability_modes/DCM_E_PENDING]
        arg OpStatus: type=Dcm_OpStatusType, direction=IN
        arg ErrorCode: type=Dcm_NegativeResponseCodeType, direction=OUT
      error E_NOT_OK: error-code=1
      error DCM_E_PENDING: error-code=10
    DataServices_Number_of_external_USB_devices_plugged_E00B_Number_of_external_USB_devices_plugged
      operation ReadData: possible-error=[DataServices_Number_of_external_USB_devices_plugged_E00B_Number_of_external_USB_devices_plugged/E_NOT_OK, DataServices_Number_of_external_USB_devices_plugged_E00B_Number_of_external_USB_devices_plugged/DCM_E_PENDING]
        arg OpStatus: type=Dcm_OpStatusType, direction=IN
        arg Data: type=Dcm_Data1ByteType, direction=OUT
      operation ConditionCheckRead: possible-error=[DataServices_Number_of_external_USB_devices_plugged_E00B_Number_of_external_USB_devices_plugged/E_NOT_OK, DataServices_Number_of_external_USB_devices_plugged_E00B_Number_of_external_USB_devices_plugged/DCM_E_PENDING]
        arg OpStatus: type=Dcm_OpStatusType, direction=IN
        arg ErrorCode: type=Dcm_NegativeResponseCodeType, direction=OUT
      error E_NOT_OK: error-code=1
      error DCM_E_PENDING: error-code=10
    DataServices_AME_Set_WIFI_Mode_FD67_WiFi_Mode
      operation WriteData: possible-error=[DataServices_AME_Set_WIFI_Mode_FD67_WiFi_Mode/E_NOT_OK, DataServices_AME_Set_WIFI_Mode_FD67_WiFi_Mode/DCM_E_PENDING]
        arg Data: type=Dcm_Data1ByteType, direction=IN
        arg OpStatus: type=Dcm_OpStatusType, direction=IN
        arg ErrorCode: type=Dcm_NegativeResponseCodeType, direction=OUT
      error E_NOT_OK: error-code=1
      error DCM_E_PENDING: error-code=10
    DataServices_Support_AM_frequency_Max_E00E_Support_AM_frequency_Max
      operation ReadData: possible-error=[DataServices_Support_AM_frequency_Max_E00E_Support_AM_frequency_Max/E_NOT_OK, DataServices_Support_AM_frequency_Max_E00E_Support_AM_frequency_Max/DCM_E_PENDING]
        arg OpStatus: type=Dcm_OpStatusType, direction=IN
        arg Data: type=Dcm_Data4ByteType, direction=OUT
      operation ConditionCheckRead: possible-error=[DataServices_Support_AM_frequency_Max_E00E_Support_AM_frequency_Max/E_NOT_OK, DataServices_Support_AM_frequency_Max_E00E_Support_AM_frequency_Max/DCM_E_PENDING]
        arg OpStatus: type=Dcm_OpStatusType, direction=IN
        arg ErrorCode: type=Dcm_NegativeResponseCodeType, direction=OUT
      error E_NOT_OK: error-code=1
      error DCM_E_PENDING: error-code=10
    DataServices_Vehicle_Manufacture_Spare_Part_Number_F187_Vehicle_Manufacture_Spare_Part_Number
      operation ReadData: possible-error=[DataServices_Vehicle_Manufacture_Spare_Part_Number_F187_Vehicle_Manufacture_Spare_Part_Number/E_NOT_OK, DataServices_Vehicle_Manufacture_Spare_Part_Number_F187_Vehicle_Manufacture_Spare_Part_Number/DCM_E_PENDING]
        arg OpStatus: type=Dcm_OpStatusType, direction=IN
        arg Data: type=Dcm_Data15ByteType, direction=OUT
      operation ConditionCheckRead: possible-error=[DataServices_Vehicle_Manufacture_Spare_Part_Number_F187_Vehicle_Manufacture_Spare_Part_Number/E_NOT_OK, DataServices_Vehicle_Manufacture_Spare_Part_Number_F187_Vehicle_Manufacture_Spare_Part_Number/DCM_E_PENDING]
        arg OpStatus: type=Dcm_OpStatusType, direction=IN
        arg ErrorCode: type=Dcm_NegativeResponseCodeType, direction=OUT
      error E_NOT_OK: error-code=1
      error DCM_E_PENDING: error-code=10
    DataServices_AME_BT_Handfree_Loopback_Test_FD6B_Reserved_Byte
      operation WriteData: possible-error=[DataServices_AME_BT_Handfree_Loopback_Test_FD6B_Reserved_Byte/E_NOT_OK, DataServices_AME_BT_Handfree_Loopback_Test_FD6B_Reserved_Byte/DCM_E_PENDING]
        arg Data: type=Dcm_Data1ByteType, direction=IN
        arg OpStatus: type=Dcm_OpStatusType, direction=IN
        arg ErrorCode: type=Dcm_NegativeResponseCodeType, direction=OUT
      error E_NOT_OK: error-code=1
      error DCM_E_PENDING: error-code=10
    DataServices_AME_TrackMedia_Audio_Source_Play_FD41_TrackMedia_AudioSourcePlay
      operation WriteData: possible-error=[DataServices_AME_TrackMedia_Audio_Source_Play_FD41_TrackMedia_AudioSourcePlay/E_NOT_OK, DataServices_AME_TrackMedia_Audio_Source_Play_FD41_TrackMedia_AudioSourcePlay/DCM_E_PENDING]
        arg Data: type=Dcm_Data1ByteType, direction=IN
        arg OpStatus: type=Dcm_OpStatusType, direction=IN
        arg ErrorCode: type=Dcm_NegativeResponseCodeType, direction=OUT
      error E_NOT_OK: error-code=1
      error DCM_E_PENDING: error-code=10
    DataServices_BT_Power_Class_E007_BT_Power_Class
      operation ReadData: possible-error=[DataServices_BT_Power_Class_E007_BT_Power_Class/E_NOT_OK, DataServices_BT_Power_Class_E007_BT_Power_Class/DCM_E_PENDING]
        arg OpStatus: type=Dcm_OpStatusType, direction=IN
        arg Data: type=Dcm_Data1ByteType, direction=OUT
      operation ConditionCheckRead: possible-error=[DataServices_BT_Power_Class_E007_BT_Power_Class/E_NOT_OK, DataServices_BT_Power_Class_E007_BT_Power_Class/DCM_E_PENDING]
        arg OpStatus: type=Dcm_OpStatusType, direction=IN
        arg ErrorCode: type=Dcm_NegativeResponseCodeType, direction=OUT
      error E_NOT_OK: error-code=1
      error DCM_E_PENDING: error-code=10
    DataServices_AME_Set_FM_Frequency_FD50_FM_Frequency
      operation WriteData: possible-error=[DataServices_AME_Set_FM_Frequency_FD50_FM_Frequency/E_NOT_OK, DataServices_AME_Set_FM_Frequency_FD50_FM_Frequency/DCM_E_PENDING]
        arg Data: type=Dcm_Data3ByteType, direction=IN
        arg OpStatus: type=Dcm_OpStatusType, direction=IN
        arg ErrorCode: type=Dcm_NegativeResponseCodeType, direction=OUT
      error E_NOT_OK: error-code=1
      error DCM_E_PENDING: error-code=10
    DataServices_Set_debug_on_off_control_FDF0_CombinedDataElement
      4 x operation, all with possible-error=[DataServices_Set_debug_on_off_control_FDF0_CombinedDataElement/E_NOT_OK, DataServices_Set_debug_on_off_control_FDF0_CombinedDataElement/DCM_E_PENDING]:
        ReadData
          arg OpStatus: type=Dcm_OpStatusType, direction=IN
          arg Data: type=Dcm_Data2ByteType, direction=OUT
        ReadDataLength
          arg OpStatus: type=Dcm_OpStatusType, direction=IN
          arg DataLength: type=uint16, direction=OUT
        ConditionCheckRead
          arg OpStatus: type=Dcm_OpStatusType, direction=IN
          arg ErrorCode: type=Dcm_NegativeResponseCodeType, direction=OUT
        WriteData
          4 x arg:
            Data: type=Dcm_Data2ByteType, direction=IN
            DataLength: type=uint16, direction=IN
            OpStatus: type=Dcm_OpStatusType, direction=IN
            ErrorCode: type=Dcm_NegativeResponseCodeType, direction=OUT
      error E_NOT_OK: error-code=1
      error DCM_E_PENDING: error-code=10
    DataServices_ECU_Serial_Number_F18C_ECU_Serial_Number
      operation ReadData: possible-error=[DataServices_ECU_Serial_Number_F18C_ECU_Serial_Number/E_NOT_OK, DataServices_ECU_Serial_Number_F18C_ECU_Serial_Number/DCM_E_PENDING]
        arg OpStatus: type=Dcm_OpStatusType, direction=IN
        arg Data: type=Dcm_Data16ByteType, direction=OUT
      operation ConditionCheckRead: possible-error=[DataServices_ECU_Serial_Number_F18C_ECU_Serial_Number/E_NOT_OK, DataServices_ECU_Serial_Number_F18C_ECU_Serial_Number/DCM_E_PENDING]
        arg OpStatus: type=Dcm_OpStatusType, direction=IN
        arg ErrorCode: type=Dcm_NegativeResponseCodeType, direction=OUT
      operation WriteData: possible-error=[DataServices_ECU_Serial_Number_F18C_ECU_Serial_Number/E_NOT_OK, DataServices_ECU_Serial_Number_F18C_ECU_Serial_Number/DCM_E_PENDING]
        arg Data: type=Dcm_Data16ByteType, direction=IN
        arg OpStatus: type=Dcm_OpStatusType, direction=IN
        arg ErrorCode: type=Dcm_NegativeResponseCodeType, direction=OUT
      error E_NOT_OK: error-code=1
      error DCM_E_PENDING: error-code=10
    DataServices_System_Supplier_ECU_Hardware_Version_Number_F193_Hardware_Version_Number
      operation ReadData: possible-error=[DataServices_System_Supplier_ECU_Hardware_Version_Number_F193_Hardware_Version_Number/E_NOT_OK, DataServices_System_Supplier_ECU_Hardware_Version_Number_F193_Hardware_Version_Number/DCM_E_PENDING]
        arg OpStatus: type=Dcm_OpStatusType, direction=IN
        arg Data: type=Dcm_Data16ByteType, direction=OUT
      operation ConditionCheckRead: possible-error=[DataServices_System_Supplier_ECU_Hardware_Version_Number_F193_Hardware_Version_Number/E_NOT_OK, DataServices_System_Supplier_ECU_Hardware_Version_Number_F193_Hardware_Version_Number/DCM_E_PENDING]
        arg OpStatus: type=Dcm_OpStatusType, direction=IN
        arg ErrorCode: type=Dcm_NegativeResponseCodeType, direction=OUT
      error E_NOT_OK: error-code=1
      error DCM_E_PENDING: error-code=10
    DataServices_System_Supplier_ECU_Software_Version_Number_F195_Software_Version_Number
      operation ReadData: possible-error=[DataServices_System_Supplier_ECU_Software_Version_Number_F195_Software_Version_Number/E_NOT_OK, DataServices_System_Supplier_ECU_Software_Version_Number_F195_Software_Version_Number/DCM_E_PENDING]
        arg OpStatus: type=Dcm_OpStatusType, direction=IN
        arg Data: type=Dcm_Data16ByteType, direction=OUT
      operation ConditionCheckRead: possible-error=[DataServices_System_Supplier_ECU_Software_Version_Number_F195_Software_Version_Number/E_NOT_OK, DataServices_System_Supplier_ECU_Software_Version_Number_F195_Software_Version_Number/DCM_E_PENDING]
        arg OpStatus: type=Dcm_OpStatusType, direction=IN
        arg ErrorCode: type=Dcm_NegativeResponseCodeType, direction=OUT
      error E_NOT_OK: error-code=1
      error DCM_E_PENDING: error-code=10
    DataServices_Operating_Voltage_Value_D003_Operating_Voltage_Value
      operation ReadData: possible-error=[DataServices_Operating_Voltage_Value_D003_Operating_Voltage_Value/E_NOT_OK, DataServices_Operating_Voltage_Value_D003_Operating_Voltage_Value/DCM_E_PENDING]
        arg OpStatus: type=Dcm_OpStatusType, direction=IN
        arg Data: type=Dcm_Data1ByteType, direction=OUT
      operation ConditionCheckRead: possible-error=[DataServices_Operating_Voltage_Value_D003_Operating_Voltage_Value/E_NOT_OK, DataServices_Operating_Voltage_Value_D003_Operating_Voltage_Value/DCM_E_PENDING]
        arg OpStatus: type=Dcm_OpStatusType, direction=IN
        arg ErrorCode: type=Dcm_NegativeResponseCodeType, direction=OUT
      error E_NOT_OK: error-code=1
      error DCM_E_PENDING: error-code=10
    DataServices_AME_TBOX_communication_status_check_FD80_TBOX_status
      operation ReadData: possible-error=[DataServices_AME_TBOX_communication_status_check_FD80_TBOX_status/E_NOT_OK, DataServices_AME_TBOX_communication_status_check_FD80_TBOX_status/DCM_E_PENDING]
        arg OpStatus: type=Dcm_OpStatusType, direction=IN
        arg Data: type=Dcm_Data1ByteType, direction=OUT
      operation ConditionCheckRead: possible-error=[DataServices_AME_TBOX_communication_status_check_FD80_TBOX_status/E_NOT_OK, DataServices_AME_TBOX_communication_status_check_FD80_TBOX_status/DCM_E_PENDING]
        arg OpStatus: type=Dcm_OpStatusType, direction=IN
        arg ErrorCode: type=Dcm_NegativeResponseCodeType, direction=OUT
      error E_NOT_OK: error-code=1
      error DCM_E_PENDING: error-code=10
    DataServices_AME_Read_harman_manufactory_part_number_FD06_Harman_Manufactory_Part_Number
      operation ReadData: possible-error=[DataServices_AME_Read_harman_manufactory_part_number_FD06_Harman_Manufactory_Part_Number/E_NOT_OK, DataServices_AME_Read_harman_manufactory_part_number_FD06_Harman_Manufactory_Part_Number/DCM_E_PENDING]
        arg OpStatus: type=Dcm_OpStatusType, direction=IN
        arg Data: type=Dcm_Data28ByteType, direction=OUT
      operation ConditionCheckRead: possible-error=[DataServices_AME_Read_harman_manufactory_part_number_FD06_Harman_Manufactory_Part_Number/E_NOT_OK, DataServices_AME_Read_harman_manufactory_part_number_FD06_Harman_Manufactory_Part_Number/DCM_E_PENDING]
        arg OpStatus: type=Dcm_OpStatusType, direction=IN
        arg ErrorCode: type=Dcm_NegativeResponseCodeType, direction=OUT
      error E_NOT_OK: error-code=1
      error DCM_E_PENDING: error-code=10
    DataServices_AME_Read_FAN_speed_FD11_FAN_Speed
      operation ReadData: possible-error=[DataServices_AME_Read_FAN_speed_FD11_FAN_Speed/E_NOT_OK, DataServices_AME_Read_FAN_speed_FD11_FAN_Speed/DCM_E_PENDING]
        arg OpStatus: type=Dcm_OpStatusType, direction=IN
        arg Data: type=Dcm_Data1ByteType, direction=OUT
      operation ConditionCheckRead: possible-error=[DataServices_AME_Read_FAN_speed_FD11_FAN_Speed/E_NOT_OK, DataServices_AME_Read_FAN_speed_FD11_FAN_Speed/DCM_E_PENDING]
        arg OpStatus: type=Dcm_OpStatusType, direction=IN
        arg ErrorCode: type=Dcm_NegativeResponseCodeType, direction=OUT
      error E_NOT_OK: error-code=1
      error DCM_E_PENDING: error-code=10
    DataServices_AME_Read_Head_Unit_Connector_Status_FD90_CombinedDataElement
      operation ReadData: possible-error=[DataServices_AME_Read_Head_Unit_Connector_Status_FD90_CombinedDataElement/E_NOT_OK, DataServices_AME_Read_Head_Unit_Connector_Status_FD90_CombinedDataElement/DCM_E_PENDING]
        arg OpStatus: type=Dcm_OpStatusType, direction=IN
        arg Data: type=Dcm_Data2ByteType, direction=OUT
      operation ConditionCheckRead: possible-error=[DataServices_AME_Read_Head_Unit_Connector_Status_FD90_CombinedDataElement/E_NOT_OK, DataServices_AME_Read_Head_Unit_Connector_Status_FD90_CombinedDataElement/DCM_E_PENDING]
        arg OpStatus: type=Dcm_OpStatusType, direction=IN
        arg ErrorCode: type=Dcm_NegativeResponseCodeType, direction=OUT
      error E_NOT_OK: error-code=1
      error DCM_E_PENDING: error-code=10
    DataServices_Number_of_installed_speakers_E01C_Number_of_installed_speakers
      operation ReadData: possible-error=[DataServices_Number_of_installed_speakers_E01C_Number_of_installed_speakers/E_NOT_OK, DataServices_Number_of_installed_speakers_E01C_Number_of_installed_speakers/DCM_E_PENDING]
        arg OpStatus: type=Dcm_OpStatusType, direction=IN
        arg Data: type=Dcm_Data1ByteType, direction=OUT
      operation ConditionCheckRead: possible-error=[DataServices_Number_of_installed_speakers_E01C_Number_of_installed_speakers/E_NOT_OK, DataServices_Number_of_installed_speakers_E01C_Number_of_installed_speakers/DCM_E_PENDING]
        arg OpStatus: type=Dcm_OpStatusType, direction=IN
        arg ErrorCode: type=Dcm_NegativeResponseCodeType, direction=OUT
      error E_NOT_OK: error-code=1
      error DCM_E_PENDING: error-code=10
    DataServices_Tbox_Gateway_sub_mask_E017_Tbox_Gateway_sub_mask
      operation ReadData: possible-error=[DataServices_Tbox_Gateway_sub_mask_E017_Tbox_Gateway_sub_mask/E_NOT_OK, DataServices_Tbox_Gateway_sub_mask_E017_Tbox_Gateway_sub_mask/DCM_E_PENDING]
        arg OpStatus: type=Dcm_OpStatusType, direction=IN
        arg Data: type=Dcm_Data16ByteType, direction=OUT
      operation ConditionCheckRead: possible-error=[DataServices_Tbox_Gateway_sub_mask_E017_Tbox_Gateway_sub_mask/E_NOT_OK, DataServices_Tbox_Gateway_sub_mask_E017_Tbox_Gateway_sub_mask/DCM_E_PENDING]
        arg OpStatus: type=Dcm_OpStatusType, direction=IN
        arg ErrorCode: type=Dcm_NegativeResponseCodeType, direction=OUT
      error E_NOT_OK: error-code=1
      error DCM_E_PENDING: error-code=10
    DataServices_AME_Set_External_Output_Status_FD93_HW
      operation WriteData: possible-error=[DataServices_AME_Set_External_Output_Status_FD93_HW/E_NOT_OK, DataServices_AME_Set_External_Output_Status_FD93_HW/DCM_E_PENDING]
        arg Data: type=Dcm_Data1ByteType, direction=IN
        arg OpStatus: type=Dcm_OpStatusType, direction=IN
        arg ErrorCode: type=Dcm_NegativeResponseCodeType, direction=OUT
      error E_NOT_OK: error-code=1
      error DCM_E_PENDING: error-code=10
    DataServices_AME_Set_External_Output_Status_FD93_Status
      operation WriteData: possible-error=[DataServices_AME_Set_External_Output_Status_FD93_Status/E_NOT_OK, DataServices_AME_Set_External_Output_Status_FD93_Status/DCM_E_PENDING]
        arg Data: type=Dcm_Data1ByteType, direction=IN
        arg OpStatus: type=Dcm_OpStatusType, direction=IN
        arg ErrorCode: type=Dcm_NegativeResponseCodeType, direction=OUT
      error E_NOT_OK: error-code=1
      error DCM_E_PENDING: error-code=10
    DataServices_Present_GPS_coordinates_shift_data_E003_GPS_coordinates
      operation ReadData: possible-error=[DataServices_Present_GPS_coordinates_shift_data_E003_GPS_coordinates/E_NOT_OK, DataServices_Present_GPS_coordinates_shift_data_E003_GPS_coordinates/DCM_E_PENDING]
        arg OpStatus: type=Dcm_OpStatusType, direction=IN
        arg Data: type=Dcm_Data4ByteType, direction=OUT
      operation ConditionCheckRead: possible-error=[DataServices_Present_GPS_coordinates_shift_data_E003_GPS_coordinates/E_NOT_OK, DataServices_Present_GPS_coordinates_shift_data_E003_GPS_coordinates/DCM_E_PENDING]
        arg OpStatus: type=Dcm_OpStatusType, direction=IN
        arg ErrorCode: type=Dcm_NegativeResponseCodeType, direction=OUT
      error E_NOT_OK: error-code=1
      error DCM_E_PENDING: error-code=10
    DataServices_AME_Set_HMI_Language_FD21_Set_HMI_Language
      operation WriteData: possible-error=[DataServices_AME_Set_HMI_Language_FD21_Set_HMI_Language/E_NOT_OK, DataServices_AME_Set_HMI_Language_FD21_Set_HMI_Language/DCM_E_PENDING]
        arg Data: type=Dcm_Data1ByteType, direction=IN
        arg OpStatus: type=Dcm_OpStatusType, direction=IN
        arg ErrorCode: type=Dcm_NegativeResponseCodeType, direction=OUT
      error E_NOT_OK: error-code=1
      error DCM_E_PENDING: error-code=10
    DataServices_AME_Connectivy_OnOff_Control_FD62_BT_WiFi
      operation WriteData: possible-error=[DataServices_AME_Connectivy_OnOff_Control_FD62_BT_WiFi/E_NOT_OK, DataServices_AME_Connectivy_OnOff_Control_FD62_BT_WiFi/DCM_E_PENDING]
        arg Data: type=Dcm_Data1ByteType, direction=IN
        arg OpStatus: type=Dcm_OpStatusType, direction=IN
        arg ErrorCode: type=Dcm_NegativeResponseCodeType, direction=OUT
      error E_NOT_OK: error-code=1
      error DCM_E_PENDING: error-code=10
    DataServices_AME_Connectivy_OnOff_Control_FD62_ON_OFF
      operation WriteData: possible-error=[DataServices_AME_Connectivy_OnOff_Control_FD62_ON_OFF/E_NOT_OK, DataServices_AME_Connectivy_OnOff_Control_FD62_ON_OFF/DCM_E_PENDING]
        arg Data: type=Dcm_Data1ByteType, direction=IN
        arg OpStatus: type=Dcm_OpStatusType, direction=IN
        arg ErrorCode: type=Dcm_NegativeResponseCodeType, direction=OUT
      error E_NOT_OK: error-code=1
      error DCM_E_PENDING: error-code=10
    DataServices_AME_Input_Output_OnOff_control_FD18_OnOffModule
      operation WriteData: possible-error=[DataServices_AME_Input_Output_OnOff_control_FD18_OnOffModule/E_NOT_OK, DataServices_AME_Input_Output_OnOff_control_FD18_OnOffModule/DCM_E_PENDING]
        arg Data: type=Dcm_Data1ByteType, direction=IN
        arg OpStatus: type=Dcm_OpStatusType, direction=IN
        arg ErrorCode: type=Dcm_NegativeResponseCodeType, direction=OUT
      error E_NOT_OK: error-code=1
      error DCM_E_PENDING: error-code=10
    DataServices_AME_Input_Output_OnOff_control_FD18_OnOffValue
      operation WriteData: possible-error=[DataServices_AME_Input_Output_OnOff_control_FD18_OnOffValue/E_NOT_OK, DataServices_AME_Input_Output_OnOff_control_FD18_OnOffValue/DCM_E_PENDING]
        arg Data: type=Dcm_Data1ByteType, direction=IN
        arg OpStatus: type=Dcm_OpStatusType, direction=IN
        arg ErrorCode: type=Dcm_NegativeResponseCodeType, direction=OUT
      error E_NOT_OK: error-code=1
      error DCM_E_PENDING: error-code=10
    DataServices_AME_Write_MAC_Address_FD61_subID
      operation WriteData: possible-error=[DataServices_AME_Write_MAC_Address_FD61_subID/E_NOT_OK, DataServices_AME_Write_MAC_Address_FD61_subID/DCM_E_PENDING]
        arg Data: type=Dcm_Data1ByteType, direction=IN
        arg OpStatus: type=Dcm_OpStatusType, direction=IN
        arg ErrorCode: type=Dcm_NegativeResponseCodeType, direction=OUT
      error E_NOT_OK: error-code=1
      error DCM_E_PENDING: error-code=10
    DataServices_AME_Write_MAC_Address_FD61_A0
      operation WriteData: possible-error=[DataServices_AME_Write_MAC_Address_FD61_A0/E_NOT_OK, DataServices_AME_Write_MAC_Address_FD61_A0/DCM_E_PENDING]
        arg Data: type=Dcm_Data1ByteType, direction=IN
        arg OpStatus: type=Dcm_OpStatusType, direction=IN
        arg ErrorCode: type=Dcm_NegativeResponseCodeType, direction=OUT
      error E_NOT_OK: error-code=1
      error DCM_E_PENDING: error-code=10
    DataServices_AME_Write_MAC_Address_FD61_A1
      operation WriteData: possible-error=[DataServices_AME_Write_MAC_Address_FD61_A1/E_NOT_OK, DataServices_AME_Write_MAC_Address_FD61_A1/DCM_E_PENDING]
        arg Data: type=Dcm_Data1ByteType, direction=IN
        arg OpStatus: type=Dcm_OpStatusType, direction=IN
        arg ErrorCode: type=Dcm_NegativeResponseCodeType, direction=OUT
      error E_NOT_OK: error-code=1
      error DCM_E_PENDING: error-code=10
    DataServices_AME_Write_MAC_Address_FD61_A2
      operation WriteData: possible-error=[DataServices_AME_Write_MAC_Address_FD61_A2/E_NOT_OK, DataServices_AME_Write_MAC_Address_FD61_A2/DCM_E_PENDING]
        arg Data: type=Dcm_Data1ByteType, direction=IN
        arg OpStatus: type=Dcm_OpStatusType, direction=IN
        arg ErrorCode: type=Dcm_NegativeResponseCodeType, direction=OUT
      error E_NOT_OK: error-code=1
      error DCM_E_PENDING: error-code=10
    DataServices_AME_Write_MAC_Address_FD61_A3
      operation WriteData: possible-error=[DataServices_AME_Write_MAC_Address_FD61_A3/E_NOT_OK, DataServices_AME_Write_MAC_Address_FD61_A3/DCM_E_PENDING]
        arg Data: type=Dcm_Data1ByteType, direction=IN
        arg OpStatus: type=Dcm_OpStatusType, direction=IN
        arg ErrorCode: type=Dcm_NegativeResponseCodeType, direction=OUT
      error E_NOT_OK: error-code=1
      error DCM_E_PENDING: error-code=10
    DataServices_AME_Write_MAC_Address_FD61_A4
      operation WriteData: possible-error=[DataServices_AME_Write_MAC_Address_FD61_A4/E_NOT_OK, DataServices_AME_Write_MAC_Address_FD61_A4/DCM_E_PENDING]
        arg Data: type=Dcm_Data1ByteType, direction=IN
        arg OpStatus: type=Dcm_OpStatusType, direction=IN
        arg ErrorCode: type=Dcm_NegativeResponseCodeType, direction=OUT
      error E_NOT_OK: error-code=1
      error DCM_E_PENDING: error-code=10
    DataServices_AME_Write_MAC_Address_FD61_A5
      operation WriteData: possible-error=[DataServices_AME_Write_MAC_Address_FD61_A5/E_NOT_OK, DataServices_AME_Write_MAC_Address_FD61_A5/DCM_E_PENDING]
        arg Data: type=Dcm_Data1ByteType, direction=IN
        arg OpStatus: type=Dcm_OpStatusType, direction=IN
        arg ErrorCode: type=Dcm_NegativeResponseCodeType, direction=OUT
      error E_NOT_OK: error-code=1
      error DCM_E_PENDING: error-code=10
    DataServices_C_matrix_Version_of_the_ECU_product_F1A2_C_matrix_Version
      operation ReadData: possible-error=[DataServices_C_matrix_Version_of_the_ECU_product_F1A2_C_matrix_Version/E_NOT_OK, DataServices_C_matrix_Version_of_the_ECU_product_F1A2_C_matrix_Version/DCM_E_PENDING]
        arg OpStatus: type=Dcm_OpStatusType, direction=IN
        arg Data: type=Dcm_Data10ByteType, direction=OUT
      operation ConditionCheckRead: possible-error=[DataServices_C_matrix_Version_of_the_ECU_product_F1A2_C_matrix_Version/E_NOT_OK, DataServices_C_matrix_Version_of_the_ECU_product_F1A2_C_matrix_Version/DCM_E_PENDING]
        arg OpStatus: type=Dcm_OpStatusType, direction=IN
        arg ErrorCode: type=Dcm_NegativeResponseCodeType, direction=OUT
      error E_NOT_OK: error-code=1
      error DCM_E_PENDING: error-code=10
    DataServices_Switch_HU_boot_mode_FDF1_Boot_Mode
      operation WriteData: possible-error=[DataServices_Switch_HU_boot_mode_FDF1_Boot_Mode/E_NOT_OK, DataServices_Switch_HU_boot_mode_FDF1_Boot_Mode/DCM_E_PENDING]
        arg Data: type=Dcm_Data1ByteType, direction=IN
        arg OpStatus: type=Dcm_OpStatusType, direction=IN
        arg ErrorCode: type=Dcm_NegativeResponseCodeType, direction=OUT
      error E_NOT_OK: error-code=1
      error DCM_E_PENDING: error-code=10
    DataServices_AME_Read_MAC_Address_FD60_CombinedDataElement
      operation ReadData: possible-error=[DataServices_AME_Read_MAC_Address_FD60_CombinedDataElement/E_NOT_OK, DataServices_AME_Read_MAC_Address_FD60_CombinedDataElement/DCM_E_PENDING]
        arg OpStatus: type=Dcm_OpStatusType, direction=IN
        arg Data: type=Dcm_Data6ByteType, direction=OUT
      operation ReadDataLength: possible-error=[DataServices_AME_Read_MAC_Address_FD60_CombinedDataElement/E_NOT_OK, DataServices_AME_Read_MAC_Address_FD60_CombinedDataElement/DCM_E_PENDING]
        arg OpStatus: type=Dcm_OpStatusType, direction=IN
        arg DataLength: type=uint16, direction=OUT
      operation ConditionCheckRead: possible-error=[DataServices_AME_Read_MAC_Address_FD60_CombinedDataElement/E_NOT_OK, DataServices_AME_Read_MAC_Address_FD60_CombinedDataElement/DCM_E_PENDING]
        arg OpStatus: type=Dcm_OpStatusType, direction=IN
        arg ErrorCode: type=Dcm_NegativeResponseCodeType, direction=OUT
      error E_NOT_OK: error-code=1
      error DCM_E_PENDING: error-code=10
    DataServices_AME_Read_AME_diagnostic_version_FD08_CombinedDataElement
      operation ReadData: possible-error=[DataServices_AME_Read_AME_diagnostic_version_FD08_CombinedDataElement/E_NOT_OK, DataServices_AME_Read_AME_diagnostic_version_FD08_CombinedDataElement/DCM_E_PENDING]
        arg OpStatus: type=Dcm_OpStatusType, direction=IN
        arg Data: type=Dcm_Data17ByteType, direction=OUT
      operation ReadDataLength: possible-error=[DataServices_AME_Read_AME_diagnostic_version_FD08_CombinedDataElement/E_NOT_OK, DataServices_AME_Read_AME_diagnostic_version_FD08_CombinedDataElement/DCM_E_PENDING]
        arg OpStatus: type=Dcm_OpStatusType, direction=IN
        arg DataLength: type=uint16, direction=OUT
      operation ConditionCheckRead: possible-error=[DataServices_AME_Read_AME_diagnostic_version_FD08_CombinedDataElement/E_NOT_OK, DataServices_AME_Read_AME_diagnostic_version_FD08_CombinedDataElement/DCM_E_PENDING]
        arg OpStatus: type=Dcm_OpStatusType, direction=IN
        arg ErrorCode: type=Dcm_NegativeResponseCodeType, direction=OUT
      error E_NOT_OK: error-code=1
      error DCM_E_PENDING: error-code=10
    DataServices_VehicleNetworkConfiguration_F1A1_VehicleNetworkConfiguration
      operation ReadData: possible-error=[DataServices_VehicleNetworkConfiguration_F1A1_VehicleNetworkConfiguration/E_NOT_OK, DataServices_VehicleNetworkConfiguration_F1A1_VehicleNetworkConfiguration/DCM_E_PENDING]
        arg OpStatus: type=Dcm_OpStatusType, direction=IN
        arg Data: type=Dcm_Data17ByteType, direction=OUT
      operation ConditionCheckRead: possible-error=[DataServices_VehicleNetworkConfiguration_F1A1_VehicleNetworkConfiguration/E_NOT_OK, DataServices_VehicleNetworkConfiguration_F1A1_VehicleNetworkConfiguration/DCM_E_PENDING]
        arg OpStatus: type=Dcm_OpStatusType, direction=IN
        arg ErrorCode: type=Dcm_NegativeResponseCodeType, direction=OUT
      operation WriteData: possible-error=[DataServices_VehicleNetworkConfiguration_F1A1_VehicleNetworkConfiguration/E_NOT_OK, DataServices_VehicleNetworkConfiguration_F1A1_VehicleNetworkConfiguration/DCM_E_PENDING]
        arg Data: type=Dcm_Data17ByteType, direction=IN
        arg OpStatus: type=Dcm_OpStatusType, direction=IN
        arg ErrorCode: type=Dcm_NegativeResponseCodeType, direction=OUT
      error E_NOT_OK: error-code=1
      error DCM_E_PENDING: error-code=10
    DataServices_Engine_Speed_D002_Engine_Speed
      operation ReadData: possible-error=[DataServices_Engine_Speed_D002_Engine_Speed/E_NOT_OK, DataServices_Engine_Speed_D002_Engine_Speed/DCM_E_PENDING]
        arg OpStatus: type=Dcm_OpStatusType, direction=IN
        arg Data: type=Dcm_Data2ByteType, direction=OUT
      operation ConditionCheckRead: possible-error=[DataServices_Engine_Speed_D002_Engine_Speed/E_NOT_OK, DataServices_Engine_Speed_D002_Engine_Speed/DCM_E_PENDING]
        arg OpStatus: type=Dcm_OpStatusType, direction=IN
        arg ErrorCode: type=Dcm_NegativeResponseCodeType, direction=OUT
      error E_NOT_OK: error-code=1
      error DCM_E_PENDING: error-code=10
    DataServices_Screen_resolution_E002_Height
      operation ReadData: possible-error=[DataServices_Screen_resolution_E002_Height/E_NOT_OK, DataServices_Screen_resolution_E002_Height/DCM_E_PENDING]
        arg OpStatus: type=Dcm_OpStatusType, direction=IN
        arg Data: type=Dcm_Data2ByteType, direction=OUT
      operation ConditionCheckRead: possible-error=[DataServices_Screen_resolution_E002_Height/E_NOT_OK, DataServices_Screen_resolution_E002_Height/DCM_E_PENDING]
        arg OpStatus: type=Dcm_OpStatusType, direction=IN
        arg ErrorCode: type=Dcm_NegativeResponseCodeType, direction=OUT
      error E_NOT_OK: error-code=1
      error DCM_E_PENDING: error-code=10
    DataServices_Screen_resolution_E002_Width
      operation ReadData: possible-error=[DataServices_Screen_resolution_E002_Width/E_NOT_OK, DataServices_Screen_resolution_E002_Width/DCM_E_PENDING]
        arg OpStatus: type=Dcm_OpStatusType, direction=IN
        arg Data: type=Dcm_Data2ByteType, direction=OUT
      operation ConditionCheckRead: possible-error=[DataServices_Screen_resolution_E002_Width/E_NOT_OK, DataServices_Screen_resolution_E002_Width/DCM_E_PENDING]
        arg OpStatus: type=Dcm_OpStatusType, direction=IN
        arg ErrorCode: type=Dcm_NegativeResponseCodeType, direction=OUT
      error E_NOT_OK: error-code=1
      error DCM_E_PENDING: error-code=10
    DataServices_AME_Read_system_voltage_FD14_CombinedDataElement
      operation ReadData: possible-error=[DataServices_AME_Read_system_voltage_FD14_CombinedDataElement/E_NOT_OK, DataServices_AME_Read_system_voltage_FD14_CombinedDataElement/DCM_E_PENDING]
        arg OpStatus: type=Dcm_OpStatusType, direction=IN
        arg Data: type=Dcm_Data2ByteType, direction=OUT
      operation ConditionCheckRead: possible-error=[DataServices_AME_Read_system_voltage_FD14_CombinedDataElement/E_NOT_OK, DataServices_AME_Read_system_voltage_FD14_CombinedDataElement/DCM_E_PENDING]
        arg OpStatus: type=Dcm_OpStatusType, direction=IN
        arg ErrorCode: type=Dcm_NegativeResponseCodeType, direction=OUT
      error E_NOT_OK: error-code=1
      error DCM_E_PENDING: error-code=10
    DataServices_Tbox_IP_Address_E016_Tbox_IP_Address
      operation ReadData: possible-error=[DataServices_Tbox_IP_Address_E016_Tbox_IP_Address/E_NOT_OK, DataServices_Tbox_IP_Address_E016_Tbox_IP_Address/DCM_E_PENDING]
        arg OpStatus: type=Dcm_OpStatusType, direction=IN
        arg Data: type=Dcm_Data16ByteType, direction=OUT
      operation ConditionCheckRead: possible-error=[DataServices_Tbox_IP_Address_E016_Tbox_IP_Address/E_NOT_OK, DataServices_Tbox_IP_Address_E016_Tbox_IP_Address/DCM_E_PENDING]
        arg OpStatus: type=Dcm_OpStatusType, direction=IN
        arg ErrorCode: type=Dcm_NegativeResponseCodeType, direction=OUT
      error E_NOT_OK: error-code=1
      error DCM_E_PENDING: error-code=10
    DataServices_DTC_Occurrence_Timer_D005_Occure_Time_Inforamation
      operation ReadData: possible-error=[DataServices_DTC_Occurrence_Timer_D005_Occure_Time_Inforamation/E_NOT_OK, DataServices_DTC_Occurrence_Timer_D005_Occure_Time_Inforamation/DCM_E_PENDING]
        arg OpStatus: type=Dcm_OpStatusType, direction=IN
        arg Data: type=Dcm_Data4ByteType, direction=OUT
      operation ConditionCheckRead: possible-error=[DataServices_DTC_Occurrence_Timer_D005_Occure_Time_Inforamation/E_NOT_OK, DataServices_DTC_Occurrence_Timer_D005_Occure_Time_Inforamation/DCM_E_PENDING]
        arg OpStatus: type=Dcm_OpStatusType, direction=IN
        arg ErrorCode: type=Dcm_NegativeResponseCodeType, direction=OUT
      error E_NOT_OK: error-code=1
      error DCM_E_PENDING: error-code=10
    DataServices_INVALID_SHORTNAME_AME_Reset_Factory_Mode_FD05_Reset_Factory_Mode
      operation WriteData: possible-error=[DataServices_INVALID_SHORTNAME_AME_Reset_Factory_Mode_FD05_Reset_Factory_Mode/E_NOT_OK, DataServices_INVALID_SHORTNAME_AME_Reset_Factory_Mode_FD05_Reset_Factory_Mode/DCM_E_PENDING]
        arg Data: type=Dcm_Data1ByteType, direction=IN
        arg OpStatus: type=Dcm_OpStatusType, direction=IN
        arg ErrorCode: type=Dcm_NegativeResponseCodeType, direction=OUT
      error E_NOT_OK: error-code=1
      error DCM_E_PENDING: error-code=10
    DataServices_Tbox_geographical_coordinates_when_connection_lost_E019_Tbox_geographical_coordinates_when_connection_lost
      operation ReadData: possible-error=[DataServices_Tbox_geographical_coordinates_when_connection_lost_E019_Tbox_geographical_coordinates_when_connection_lost/E_NOT_OK, DataServices_Tbox_geographical_coordinates_when_connection_lost_E019_Tbox_geographical_coordinates_when_connection_lost/DCM_E_PENDING]
        arg OpStatus: type=Dcm_OpStatusType, direction=IN
        arg Data: type=Dcm_Data16ByteType, direction=OUT
      operation ConditionCheckRead: possible-error=[DataServices_Tbox_geographical_coordinates_when_connection_lost_E019_Tbox_geographical_coordinates_when_connection_lost/E_NOT_OK, DataServices_Tbox_geographical_coordinates_when_connection_lost_E019_Tbox_geographical_coordinates_when_connection_lost/DCM_E_PENDING]
        arg OpStatus: type=Dcm_OpStatusType, direction=IN
        arg ErrorCode: type=Dcm_NegativeResponseCodeType, direction=OUT
      error E_NOT_OK: error-code=1
      error DCM_E_PENDING: error-code=10
    DataServices_AME_Read_GYRO_Status_FD71_GYRO_Status
      operation ReadData: possible-error=[DataServices_AME_Read_GYRO_Status_FD71_GYRO_Status/E_NOT_OK, DataServices_AME_Read_GYRO_Status_FD71_GYRO_Status/DCM_E_PENDING]
        arg OpStatus: type=Dcm_OpStatusType, direction=IN
        arg Data: type=Dcm_Data1ByteType, direction=OUT
      operation ConditionCheckRead: possible-error=[DataServices_AME_Read_GYRO_Status_FD71_GYRO_Status/E_NOT_OK, DataServices_AME_Read_GYRO_Status_FD71_GYRO_Status/DCM_E_PENDING]
        arg OpStatus: type=Dcm_OpStatusType, direction=IN
        arg ErrorCode: type=Dcm_NegativeResponseCodeType, direction=OUT
      error E_NOT_OK: error-code=1
      error DCM_E_PENDING: error-code=10
    DataServices_Wi_Fi_Module_Firmware_Version_E014_Wi_Fi_Module_Firmware_Version
      operation ReadData: possible-error=[DataServices_Wi_Fi_Module_Firmware_Version_E014_Wi_Fi_Module_Firmware_Version/E_NOT_OK, DataServices_Wi_Fi_Module_Firmware_Version_E014_Wi_Fi_Module_Firmware_Version/DCM_E_PENDING]
        arg OpStatus: type=Dcm_OpStatusType, direction=IN
        arg Data: type=Dcm_Data16ByteType, direction=OUT
      operation ConditionCheckRead: possible-error=[DataServices_Wi_Fi_Module_Firmware_Version_E014_Wi_Fi_Module_Firmware_Version/E_NOT_OK, DataServices_Wi_Fi_Module_Firmware_Version_E014_Wi_Fi_Module_Firmware_Version/DCM_E_PENDING]
        arg OpStatus: type=Dcm_OpStatusType, direction=IN
        arg ErrorCode: type=Dcm_NegativeResponseCodeType, direction=OUT
      error E_NOT_OK: error-code=1
      error DCM_E_PENDING: error-code=10
    DataServices_AME_Select_Speaker_Zone_FD33_Select_Speaker_Zone
      operation WriteData: possible-error=[DataServices_AME_Select_Speaker_Zone_FD33_Select_Speaker_Zone/E_NOT_OK, DataServices_AME_Select_Speaker_Zone_FD33_Select_Speaker_Zone/DCM_E_PENDING]
        arg Data: type=Dcm_Data1ByteType, direction=IN
        arg OpStatus: type=Dcm_OpStatusType, direction=IN
        arg ErrorCode: type=Dcm_NegativeResponseCodeType, direction=OUT
      error E_NOT_OK: error-code=1
      error DCM_E_PENDING: error-code=10
    DataServices_AME_Play_BT_Audio_Control_FD64_Reserved_Byte
      operation WriteData: possible-error=[DataServices_AME_Play_BT_Audio_Control_FD64_Reserved_Byte/E_NOT_OK, DataServices_AME_Play_BT_Audio_Control_FD64_Reserved_Byte/DCM_E_PENDING]
        arg Data: type=Dcm_Data1ByteType, direction=IN
        arg OpStatus: type=Dcm_OpStatusType, direction=IN
        arg ErrorCode: type=Dcm_NegativeResponseCodeType, direction=OUT
      error E_NOT_OK: error-code=1
      error DCM_E_PENDING: error-code=10
    DataServices_AME_Switch_BIOS_Mode_FD02_Switch_BIOS
      operation WriteData: possible-error=[DataServices_AME_Switch_BIOS_Mode_FD02_Switch_BIOS/E_NOT_OK, DataServices_AME_Switch_BIOS_Mode_FD02_Switch_BIOS/DCM_E_PENDING]
        arg Data: type=Dcm_Data1ByteType, direction=IN
        arg OpStatus: type=Dcm_OpStatusType, direction=IN
        arg ErrorCode: type=Dcm_NegativeResponseCodeType, direction=OUT
      error E_NOT_OK: error-code=1
      error DCM_E_PENDING: error-code=10
    DataServices_AME_Ethernet_IP_Ping_Function_FD6E_IPAddress_Byte3
      operation WriteData: possible-error=[DataServices_AME_Ethernet_IP_Ping_Function_FD6E_IPAddress_Byte3/E_NOT_OK, DataServices_AME_Ethernet_IP_Ping_Function_FD6E_IPAddress_Byte3/DCM_E_PENDING]
        arg Data: type=Dcm_Data1ByteType, direction=IN
        arg OpStatus: type=Dcm_OpStatusType, direction=IN
        arg ErrorCode: type=Dcm_NegativeResponseCodeType, direction=OUT
      error E_NOT_OK: error-code=1
      error DCM_E_PENDING: error-code=10
    DataServices_AME_Ethernet_IP_Ping_Function_FD6E_IPAddress_Byte4
      operation WriteData: possible-error=[DataServices_AME_Ethernet_IP_Ping_Function_FD6E_IPAddress_Byte4/E_NOT_OK, DataServices_AME_Ethernet_IP_Ping_Function_FD6E_IPAddress_Byte4/DCM_E_PENDING]
        arg Data: type=Dcm_Data1ByteType, direction=IN
        arg OpStatus: type=Dcm_OpStatusType, direction=IN
        arg ErrorCode: type=Dcm_NegativeResponseCodeType, direction=OUT
      error E_NOT_OK: error-code=1
      error DCM_E_PENDING: error-code=10
    DataServices_AME_Ethernet_IP_Ping_Function_FD6E_Ethernet_Channel
      operation WriteData: possible-error=[DataServices_AME_Ethernet_IP_Ping_Function_FD6E_Ethernet_Channel/E_NOT_OK, DataServices_AME_Ethernet_IP_Ping_Function_FD6E_Ethernet_Channel/DCM_E_PENDING]
        arg Data: type=Dcm_Data1ByteType, direction=IN
        arg OpStatus: type=Dcm_OpStatusType, direction=IN
        arg ErrorCode: type=Dcm_NegativeResponseCodeType, direction=OUT
      error E_NOT_OK: error-code=1
      error DCM_E_PENDING: error-code=10
    DataServices_AME_Ethernet_IP_Ping_Function_FD6E_IPAddress_Byte1
      operation WriteData: possible-error=[DataServices_AME_Ethernet_IP_Ping_Function_FD6E_IPAddress_Byte1/E_NOT_OK, DataServices_AME_Ethernet_IP_Ping_Function_FD6E_IPAddress_Byte1/DCM_E_PENDING]
        arg Data: type=Dcm_Data1ByteType, direction=IN
        arg OpStatus: type=Dcm_OpStatusType, direction=IN
        arg ErrorCode: type=Dcm_NegativeResponseCodeType, direction=OUT
      error E_NOT_OK: error-code=1
      error DCM_E_PENDING: error-code=10
    DataServices_AME_Ethernet_IP_Ping_Function_FD6E_IPAddress_Byte2
      operation WriteData: possible-error=[DataServices_AME_Ethernet_IP_Ping_Function_FD6E_IPAddress_Byte2/E_NOT_OK, DataServices_AME_Ethernet_IP_Ping_Function_FD6E_IPAddress_Byte2/DCM_E_PENDING]
        arg Data: type=Dcm_Data1ByteType, direction=IN
        arg OpStatus: type=Dcm_OpStatusType, direction=IN
        arg ErrorCode: type=Dcm_NegativeResponseCodeType, direction=OUT
      error E_NOT_OK: error-code=1
      error DCM_E_PENDING: error-code=10
    DataServices_AM_signal_Strength_E011_AM_signal_Strength
      operation ReadData: possible-error=[DataServices_AM_signal_Strength_E011_AM_signal_Strength/E_NOT_OK, DataServices_AM_signal_Strength_E011_AM_signal_Strength/DCM_E_PENDING]
        arg OpStatus: type=Dcm_OpStatusType, direction=IN
        arg Data: type=Dcm_Data1ByteType, direction=OUT
      operation ConditionCheckRead: possible-error=[DataServices_AM_signal_Strength_E011_AM_signal_Strength/E_NOT_OK, DataServices_AM_signal_Strength_E011_AM_signal_Strength/DCM_E_PENDING]
        arg OpStatus: type=Dcm_OpStatusType, direction=IN
        arg ErrorCode: type=Dcm_NegativeResponseCodeType, direction=OUT
      error E_NOT_OK: error-code=1
      error DCM_E_PENDING: error-code=10
    DataServices_Tbox_Last_connection_lost_time_stamp_E018_Tbox_Last_connection_lost_time_stamp
      operation ReadData: possible-error=[DataServices_Tbox_Last_connection_lost_time_stamp_E018_Tbox_Last_connection_lost_time_stamp/E_NOT_OK, DataServices_Tbox_Last_connection_lost_time_stamp_E018_Tbox_Last_connection_lost_time_stamp/DCM_E_PENDING]
        arg OpStatus: type=Dcm_OpStatusType, direction=IN
        arg Data: type=Dcm_Data16ByteType, direction=OUT
      operation ConditionCheckRead: possible-error=[DataServices_Tbox_Last_connection_lost_time_stamp_E018_Tbox_Last_connection_lost_time_stamp/E_NOT_OK, DataServices_Tbox_Last_connection_lost_time_stamp_E018_Tbox_Last_connection_lost_time_stamp/DCM_E_PENDING]
        arg OpStatus: type=Dcm_OpStatusType, direction=IN
        arg ErrorCode: type=Dcm_NegativeResponseCodeType, direction=OUT
      error E_NOT_OK: error-code=1
      error DCM_E_PENDING: error-code=10
    DataServices_AME_Read_Detection_Input_Info_FD92_CombinedDataElement
      operation ReadData: possible-error=[DataServices_AME_Read_Detection_Input_Info_FD92_CombinedDataElement/E_NOT_OK, DataServices_AME_Read_Detection_Input_Info_FD92_CombinedDataElement/DCM_E_PENDING]
        arg OpStatus: type=Dcm_OpStatusType, direction=IN
        arg Data: type=Dcm_Data2ByteType, direction=OUT
      operation ConditionCheckRead: possible-error=[DataServices_AME_Read_Detection_Input_Info_FD92_CombinedDataElement/E_NOT_OK, DataServices_AME_Read_Detection_Input_Info_FD92_CombinedDataElement/DCM_E_PENDING]
        arg OpStatus: type=Dcm_OpStatusType, direction=IN
        arg ErrorCode: type=Dcm_NegativeResponseCodeType, direction=OUT
      error E_NOT_OK: error-code=1
      error DCM_E_PENDING: error-code=10
    DataServices_Data_DID_StartApplication
      operation ReadData: possible-error=DataServices_Data_DID_StartApplication/E_NOT_OK
        arg Data: type=Dcm_Data2ByteType, direction=OUT
      operation ConditionCheckRead: possible-error=DataServices_Data_DID_StartApplication/E_NOT_OK
        arg ErrorCode: type=Dcm_NegativeResponseCodeType, direction=OUT
      operation WriteData: possible-error=DataServices_Data_DID_StartApplication/E_NOT_OK
        arg Data: type=Dcm_Data2ByteType, direction=IN
        arg ErrorCode: type=Dcm_NegativeResponseCodeType, direction=OUT
      error E_NOT_OK: error-code=1
  mode switch interface DcmCommunicationControl_ComMConf_ComMChannel_CN_CAN_fe6ecc87: is-service=true, service-kind=DIAGNOSTIC-COMMUNICATION-MANAGER
    mode group DcmCommunicationControl_ComMConf_ComMChannel_CN_CAN_fe6ecc87: type=DcmCommunicationControl
package /MICROSAR/Dcm_swc/ComponentTypes
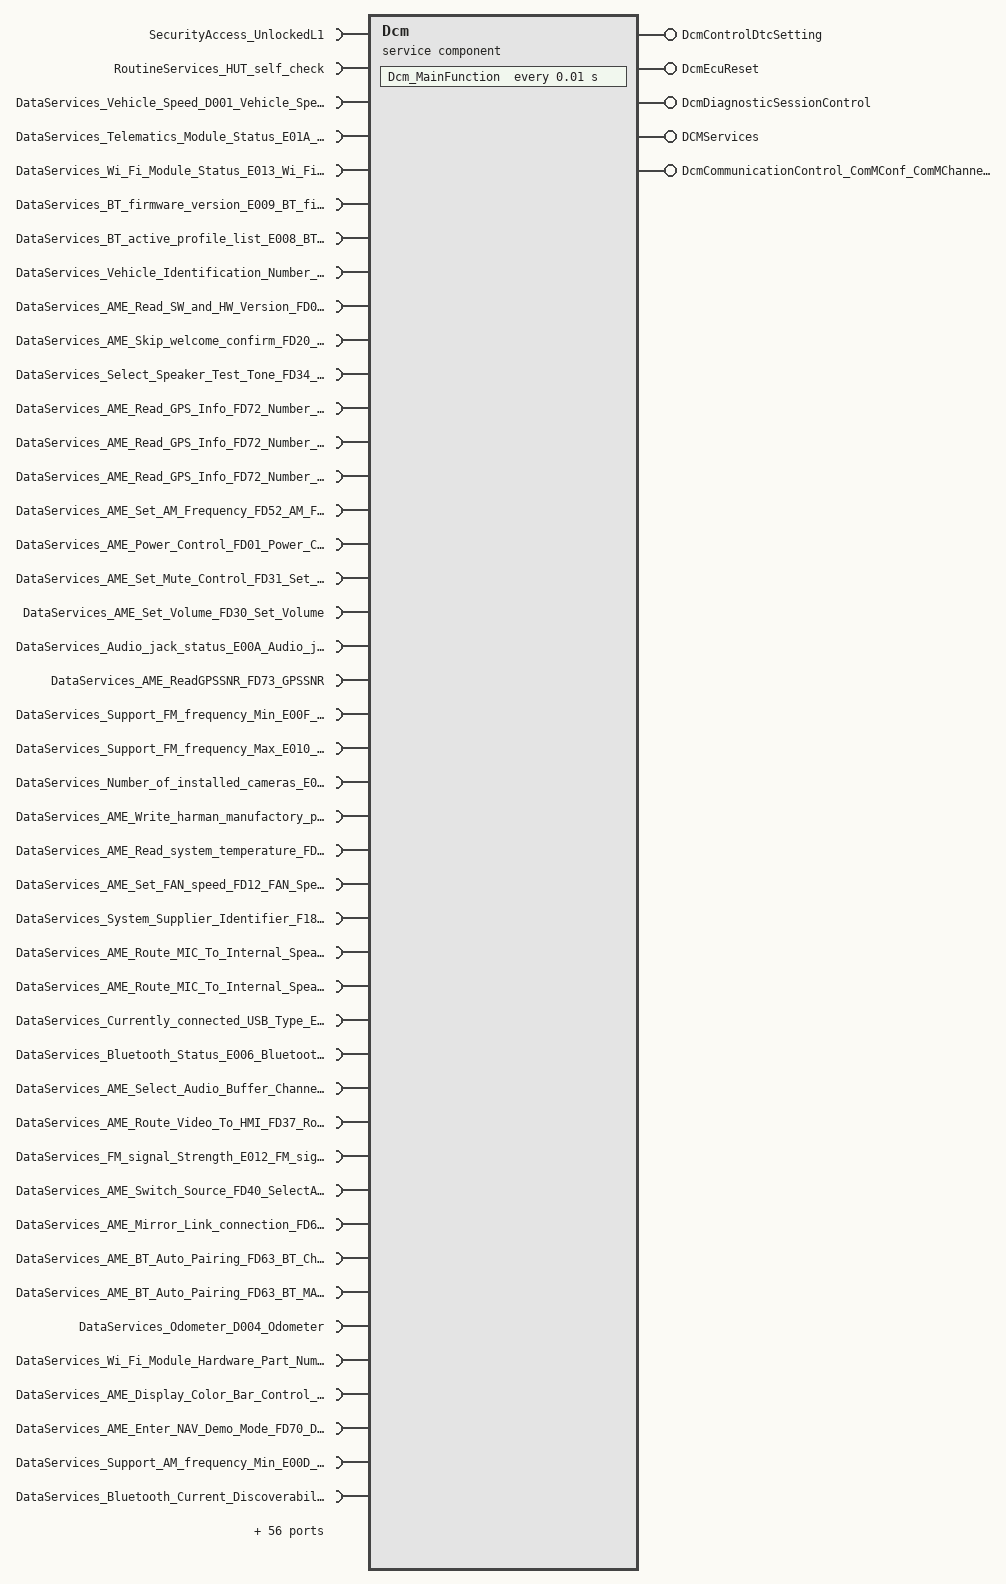
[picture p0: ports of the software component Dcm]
  service sw component type Dcm: category=SERVICE_COMPONENT
    4 x provide port:
      DcmControlDtcSetting: provided-interface=DcmControlDtcSetting
      DcmEcuReset: mode-switch-sender-com-spec{mode-group=DcmEcuReset, mode-switched-ack=timeout=0}, provided-interface=DcmEcuReset
      DcmDiagnosticSessionControl: provided-interface=DcmDiagnosticSessionControl
      DCMServices: provided-interface=DCMServices
    105 x require port:
      SecurityAccess_UnlockedL1: required-interface=SecurityAccess_UnlockedL1
      RoutineServices_HUT_self_check: required-interface=RoutineServices_HUT_self_check
      DataServices_Vehicle_Speed_D001_Vehicle_Speed: required-interface=DataServices_Vehicle_Speed_D001_Vehicle_Speed
      DataServices_Telematics_Module_Status_E01A_Telematics_Module_Status: required-interface=DataServices_Telematics_Module_Status_E01A_Telematics_Module_Status
      DataServices_Wi_Fi_Module_Status_E013_Wi_Fi_Module_Status: required-interface=DataServices_Wi_Fi_Module_Status_E013_Wi_Fi_Module_Status
      DataServices_BT_firmware_version_E009_BT_firmware_version: required-interface=DataServices_BT_firmware_version_E009_BT_firmware_version
      DataServices_BT_active_profile_list_E008_BT_active_profile_list: required-interface=DataServices_BT_active_profile_list_E008_BT_active_profile_list
      DataServices_Vehicle_Identification_Number_F190_VIN: required-interface=DataServices_Vehicle_Identification_Number_F190_VIN
      DataServices_AME_Read_SW_and_HW_Version_FD04_CombinedDataElement: required-interface=DataServices_AME_Read_SW_and_HW_Version_FD04_CombinedDataElement
      DataServices_AME_Skip_welcome_confirm_FD20_Reserved_Byte: required-interface=DataServices_AME_Skip_welcome_confirm_FD20_Reserved_Byte
      DataServices_Select_Speaker_Test_Tone_FD34_Select_tone: required-interface=DataServices_Select_Speaker_Test_Tone_FD34_Select_tone
      DataServices_AME_Read_GPS_Info_FD72_Number_of_used_satellite: required-interface=DataServices_AME_Read_GPS_Info_FD72_Number_of_used_satellite
      DataServices_AME_Read_GPS_Info_FD72_Number_of_visible_staellite: required-interface=DataServices_AME_Read_GPS_Info_FD72_Number_of_visible_staellite
      DataServices_AME_Read_GPS_Info_FD72_Number_of_fix: required-interface=DataServices_AME_Read_GPS_Info_FD72_Number_of_fix
      DataServices_AME_Set_AM_Frequency_FD52_AM_Frequency: required-interface=DataServices_AME_Set_AM_Frequency_FD52_AM_Frequency
      DataServices_AME_Power_Control_FD01_Power_Control: required-interface=DataServices_AME_Power_Control_FD01_Power_Control
      DataServices_AME_Set_Mute_Control_FD31_Set_Mute_Control: required-interface=DataServices_AME_Set_Mute_Control_FD31_Set_Mute_Control
      DataServices_AME_Set_Volume_FD30_Set_Volume: required-interface=DataServices_AME_Set_Volume_FD30_Set_Volume
      DataServices_Audio_jack_status_E00A_Audio_jack_status: required-interface=DataServices_Audio_jack_status_E00A_Audio_jack_status
      DataServices_AME_ReadGPSSNR_FD73_GPSSNR: required-interface=DataServices_AME_ReadGPSSNR_FD73_GPSSNR
      DataServices_Support_FM_frequency_Min_E00F_Support_FM_frequency_Min: required-interface=DataServices_Support_FM_frequency_Min_E00F_Support_FM_frequency_Min
      DataServices_Support_FM_frequency_Max_E010_Support_FM_frequency_Max: required-interface=DataServices_Support_FM_frequency_Max_E010_Support_FM_frequency_Max
      DataServices_Number_of_installed_cameras_E001_Number_of_installed_cameras: required-interface=DataServices_Number_of_installed_cameras_E001_Number_of_installed_cameras
      DataServices_AME_Write_harman_manufactory_part_number_FD07_Harman_Manufactory_Part_Number: required-interface=DataServices_AME_Write_harman_manufactory_part_number_FD07_Harman_Manufactory_Part_Number
      DataServices_AME_Read_system_temperature_FD13_CombinedDataElement: required-interface=DataServices_AME_Read_system_temperature_FD13_CombinedDataElement
      DataServices_AME_Set_FAN_speed_FD12_FAN_Speed: required-interface=DataServices_AME_Set_FAN_speed_FD12_FAN_Speed
      DataServices_System_Supplier_Identifier_F18A_System_Supplier_Identifier: required-interface=DataServices_System_Supplier_Identifier_F18A_System_Supplier_Identifier
      DataServices_AME_Route_MIC_To_Internal_Speaker_FD36_Control: required-interface=DataServices_AME_Route_MIC_To_Internal_Speaker_FD36_Control
      DataServices_AME_Route_MIC_To_Internal_Speaker_FD36_Mic: required-interface=DataServices_AME_Route_MIC_To_Internal_Speaker_FD36_Mic
      DataServices_Currently_connected_USB_Type_E00C_Currently_connected_USB_Type: required-interface=DataServices_Currently_connected_USB_Type_E00C_Currently_connected_USB_Type
      DataServices_Bluetooth_Status_E006_Bluetooth_Status: required-interface=DataServices_Bluetooth_Status_E006_Bluetooth_Status
      DataServices_AME_Select_Audio_Buffer_Channel_Output_FD39_SelectAudioBufferChannelOutput: required-interface=DataServices_AME_Select_Audio_Buffer_Channel_Output_FD39_SelectAudioBufferChannelOutput
      DataServices_AME_Route_Video_To_HMI_FD37_Route_Vedio_To_HMI: required-interface=DataServices_AME_Route_Video_To_HMI_FD37_Route_Vedio_To_HMI
      DataServices_FM_signal_Strength_E012_FM_signal_Strength: required-interface=DataServices_FM_signal_Strength_E012_FM_signal_Strength
      DataServices_AME_Switch_Source_FD40_SelectAudioBufferChannelOutput: required-interface=DataServices_AME_Switch_Source_FD40_SelectAudioBufferChannelOutput
      DataServices_AME_Mirror_Link_connection_FD6D_Mirror_Link_connection: required-interface=DataServices_AME_Mirror_Link_connection_FD6D_Mirror_Link_connection
      DataServices_AME_BT_Auto_Pairing_FD63_BT_Chip: required-interface=DataServices_AME_BT_Auto_Pairing_FD63_BT_Chip
      DataServices_AME_BT_Auto_Pairing_FD63_BT_MAC_Address: required-interface=DataServices_AME_BT_Auto_Pairing_FD63_BT_MAC_Address
      DataServices_Odometer_D004_Odometer: required-interface=DataServices_Odometer_D004_Odometer
      DataServices_Wi_Fi_Module_Hardware_Part_Number_E015_Wi_Fi_Module_Hardware_Part_Number: required-interface=DataServices_Wi_Fi_Module_Hardware_Part_Number_E015_Wi_Fi_Module_Hardware_Part_Number
      DataServices_AME_Display_Color_Bar_Control_FD38_Display_Color_Bar_Control: required-interface=DataServices_AME_Display_Color_Bar_Control_FD38_Display_Color_Bar_Control
      DataServices_AME_Enter_NAV_Demo_Mode_FD70_Demo_Mode: required-interface=DataServices_AME_Enter_NAV_Demo_Mode_FD70_Demo_Mode
      DataServices_Support_AM_frequency_Min_E00D_Support_AM_frequency_Min: required-interface=DataServices_Support_AM_frequency_Min_E00D_Support_AM_frequency_Min
      DataServices_Bluetooth_Current_Discoverability_modes_E005_Bluetooth_Current_Discoverability_modes: required-interface=DataServices_Bluetooth_Current_Discoverability_modes_E005_Bluetooth_Current_Discoverability_modes
      DataServices_Number_of_external_USB_devices_plugged_E00B_Number_of_external_USB_devices_plugged: required-interface=DataServices_Number_of_external_USB_devices_plugged_E00B_Number_of_external_USB_devices_plugged
      DataServices_AME_Set_WIFI_Mode_FD67_WiFi_Mode: required-interface=DataServices_AME_Set_WIFI_Mode_FD67_WiFi_Mode
      DataServices_Support_AM_frequency_Max_E00E_Support_AM_frequency_Max: required-interface=DataServices_Support_AM_frequency_Max_E00E_Support_AM_frequency_Max
      DataServices_Vehicle_Manufacture_Spare_Part_Number_F187_Vehicle_Manufacture_Spare_Part_Number: required-interface=DataServices_Vehicle_Manufacture_Spare_Part_Number_F187_Vehicle_Manufacture_Spare_Part_Number
      DataServices_AME_BT_Handfree_Loopback_Test_FD6B_Reserved_Byte: required-interface=DataServices_AME_BT_Handfree_Loopback_Test_FD6B_Reserved_Byte
      DataServices_AME_TrackMedia_Audio_Source_Play_FD41_TrackMedia_AudioSourcePlay: required-interface=DataServices_AME_TrackMedia_Audio_Source_Play_FD41_TrackMedia_AudioSourcePlay
      DataServices_BT_Power_Class_E007_BT_Power_Class: required-interface=DataServices_BT_Power_Class_E007_BT_Power_Class
      DataServices_AME_Set_FM_Frequency_FD50_FM_Frequency: required-interface=DataServices_AME_Set_FM_Frequency_FD50_FM_Frequency
      DataServices_Set_debug_on_off_control_FDF0_CombinedDataElement: required-interface=DataServices_Set_debug_on_off_control_FDF0_CombinedDataElement
      DataServices_ECU_Serial_Number_F18C_ECU_Serial_Number: required-interface=DataServices_ECU_Serial_Number_F18C_ECU_Serial_Number
      DataServices_System_Supplier_ECU_Hardware_Version_Number_F193_Hardware_Version_Number: required-interface=DataServices_System_Supplier_ECU_Hardware_Version_Number_F193_Hardware_Version_Number
      DataServices_System_Supplier_ECU_Software_Version_Number_F195_Software_Version_Number: required-interface=DataServices_System_Supplier_ECU_Software_Version_Number_F195_Software_Version_Number
      DataServices_Operating_Voltage_Value_D003_Operating_Voltage_Value: required-interface=DataServices_Operating_Voltage_Value_D003_Operating_Voltage_Value
      DataServices_AME_TBOX_communication_status_check_FD80_TBOX_status: required-interface=DataServices_AME_TBOX_communication_status_check_FD80_TBOX_status
      DataServices_AME_Read_harman_manufactory_part_number_FD06_Harman_Manufactory_Part_Number: required-interface=DataServices_AME_Read_harman_manufactory_part_number_FD06_Harman_Manufactory_Part_Number
      DataServices_AME_Read_FAN_speed_FD11_FAN_Speed: required-interface=DataServices_AME_Read_FAN_speed_FD11_FAN_Speed
      DataServices_AME_Read_Head_Unit_Connector_Status_FD90_CombinedDataElement: required-interface=DataServices_AME_Read_Head_Unit_Connector_Status_FD90_CombinedDataElement
      DataServices_Number_of_installed_speakers_E01C_Number_of_installed_speakers: required-interface=DataServices_Number_of_installed_speakers_E01C_Number_of_installed_speakers
      DataServices_Tbox_Gateway_sub_mask_E017_Tbox_Gateway_sub_mask: required-interface=DataServices_Tbox_Gateway_sub_mask_E017_Tbox_Gateway_sub_mask
      DataServices_AME_Set_External_Output_Status_FD93_HW: required-interface=DataServices_AME_Set_External_Output_Status_FD93_HW
      DataServices_AME_Set_External_Output_Status_FD93_Status: required-interface=DataServices_AME_Set_External_Output_Status_FD93_Status
      DataServices_Present_GPS_coordinates_shift_data_E003_GPS_coordinates: required-interface=DataServices_Present_GPS_coordinates_shift_data_E003_GPS_coordinates
      DataServices_AME_Set_HMI_Language_FD21_Set_HMI_Language: required-interface=DataServices_AME_Set_HMI_Language_FD21_Set_HMI_Language
      DataServices_AME_Connectivy_OnOff_Control_FD62_BT_WiFi: required-interface=DataServices_AME_Connectivy_OnOff_Control_FD62_BT_WiFi
      DataServices_AME_Connectivy_OnOff_Control_FD62_ON_OFF: required-interface=DataServices_AME_Connectivy_OnOff_Control_FD62_ON_OFF
      DataServices_AME_Input_Output_OnOff_control_FD18_OnOffModule: required-interface=DataServices_AME_Input_Output_OnOff_control_FD18_OnOffModule
      DataServices_AME_Input_Output_OnOff_control_FD18_OnOffValue: required-interface=DataServices_AME_Input_Output_OnOff_control_FD18_OnOffValue
      DataServices_AME_Write_MAC_Address_FD61_subID: required-interface=DataServices_AME_Write_MAC_Address_FD61_subID
      DataServices_AME_Write_MAC_Address_FD61_A{0..5}: required-interface=DataServices_AME_Write_MAC_Address_FD61_A{0..5}
      DataServices_C_matrix_Version_of_the_ECU_product_F1A2_C_matrix_Version: required-interface=DataServices_C_matrix_Version_of_the_ECU_product_F1A2_C_matrix_Version
      DataServices_Switch_HU_boot_mode_FDF1_Boot_Mode: required-interface=DataServices_Switch_HU_boot_mode_FDF1_Boot_Mode
      DataServices_AME_Read_MAC_Address_FD60_CombinedDataElement: required-interface=DataServices_AME_Read_MAC_Address_FD60_CombinedDataElement
      DataServices_AME_Read_AME_diagnostic_version_FD08_CombinedDataElement: required-interface=DataServices_AME_Read_AME_diagnostic_version_FD08_CombinedDataElement
      DataServices_VehicleNetworkConfiguration_F1A1_VehicleNetworkConfiguration: required-interface=DataServices_VehicleNetworkConfiguration_F1A1_VehicleNetworkConfiguration
      DataServices_Engine_Speed_D002_Engine_Speed: required-interface=DataServices_Engine_Speed_D002_Engine_Speed
      DataServices_Screen_resolution_E002_Height: required-interface=DataServices_Screen_resolution_E002_Height
      DataServices_Screen_resolution_E002_Width: required-interface=DataServices_Screen_resolution_E002_Width
      DataServices_AME_Read_system_voltage_FD14_CombinedDataElement: required-interface=DataServices_AME_Read_system_voltage_FD14_CombinedDataElement
      DataServices_Tbox_IP_Address_E016_Tbox_IP_Address: required-interface=DataServices_Tbox_IP_Address_E016_Tbox_IP_Address
      DataServices_DTC_Occurrence_Timer_D005_Occure_Time_Inforamation: required-interface=DataServices_DTC_Occurrence_Timer_D005_Occure_Time_Inforamation
      DataServices_INVALID_SHORTNAME_AME_Reset_Factory_Mode_FD05_Reset_Factory_Mode: required-interface=DataServices_INVALID_SHORTNAME_AME_Reset_Factory_Mode_FD05_Reset_Factory_Mode
      DataServices_Tbox_geographical_coordinates_when_connection_lost_E019_Tbox_geographical_coordinates_when_connection_lost: required-interface=DataServices_Tbox_geographical_coordinates_when_connection_lost_E019_Tbox_geographical_coordinates_when_connection_lost
      DataServices_AME_Read_GYRO_Status_FD71_GYRO_Status: required-interface=DataServices_AME_Read_GYRO_Status_FD71_GYRO_Status
      DataServices_Wi_Fi_Module_Firmware_Version_E014_Wi_Fi_Module_Firmware_Version: required-interface=DataServices_Wi_Fi_Module_Firmware_Version_E014_Wi_Fi_Module_Firmware_Version
      DataServices_AME_Select_Speaker_Zone_FD33_Select_Speaker_Zone: required-interface=DataServices_AME_Select_Speaker_Zone_FD33_Select_Speaker_Zone
      DataServices_AME_Play_BT_Audio_Control_FD64_Reserved_Byte: required-interface=DataServices_AME_Play_BT_Audio_Control_FD64_Reserved_Byte
      DataServices_AME_Switch_BIOS_Mode_FD02_Switch_BIOS: required-interface=DataServices_AME_Switch_BIOS_Mode_FD02_Switch_BIOS
      DataServices_AME_Ethernet_IP_Ping_Function_FD6E_IPAddress_Byte3: required-interface=DataServices_AME_Ethernet_IP_Ping_Function_FD6E_IPAddress_Byte3
      DataServices_AME_Ethernet_IP_Ping_Function_FD6E_IPAddress_Byte4: required-interface=DataServices_AME_Ethernet_IP_Ping_Function_FD6E_IPAddress_Byte4
      DataServices_AME_Ethernet_IP_Ping_Function_FD6E_Ethernet_Channel: required-interface=DataServices_AME_Ethernet_IP_Ping_Function_FD6E_Ethernet_Channel
      DataServices_AME_Ethernet_IP_Ping_Function_FD6E_IPAddress_Byte1: required-interface=DataServices_AME_Ethernet_IP_Ping_Function_FD6E_IPAddress_Byte1
      DataServices_AME_Ethernet_IP_Ping_Function_FD6E_IPAddress_Byte2: required-interface=DataServices_AME_Ethernet_IP_Ping_Function_FD6E_IPAddress_Byte2
      DataServices_AM_signal_Strength_E011_AM_signal_Strength: required-interface=DataServices_AM_signal_Strength_E011_AM_signal_Strength
      DataServices_Tbox_Last_connection_lost_time_stamp_E018_Tbox_Last_connection_lost_time_stamp: required-interface=DataServices_Tbox_Last_connection_lost_time_stamp_E018_Tbox_Last_connection_lost_time_stamp
      DataServices_AME_Read_Detection_Input_Info_FD92_CombinedDataElement: required-interface=DataServices_AME_Read_Detection_Input_Info_FD92_CombinedDataElement
      DataServices_Data_DID_StartApplication: required-interface=DataServices_Data_DID_StartApplication
    provide port DcmCommunicationControl_ComMConf_ComMChannel_CN_CAN_fe6ecc87: provided-interface=DcmCommunicationControl_ComMConf_ComMChannel_CN_CAN_fe6ecc87
    behavior DcmInternalBehavior: data-type-mapping=DcmMappingSet, handle-termination-and-restart=NO-SUPPORT, included-data-type-set=data-type=[Dcm_ConfirmationStatusType, Dcm_OpStatusType, Dcm_NegativeResponseCodeType, Dcm_ProtocolType, Dcm_RequestKindType, Dcm_SecLevelType, Dcm_SesCtrlType, Dcm_ControlDtcSettingType, Dcm_EcuResetType, Dcm_DiagnosticSessionControlType, Dcm_CommunicationModeType]
      timing event Timer_Dcm_MainFunction: start-on-event=Dcm_MainFunction, period=0.01
      6 x operation invoked event:
        OpEventGetActiveProtocol_GetActiveProtocol_DCMServices: start-on-event=GetActiveProtocol, operation=DCMServices.GetActiveProtocol
        OpEventGetSesCtrlType_GetSesCtrlType_DCMServices: start-on-event=GetSesCtrlType, operation=DCMServices.GetSesCtrlType
        OpEventResetToDefaultSession_ResetToDefaultSession_DCMServices: start-on-event=ResetToDefaultSession, operation=DCMServices.ResetToDefaultSession
        OpEventGetSecurityLevel_GetSecurityLevel_DCMServices: start-on-event=GetSecurityLevel, operation=DCMServices.GetSecurityLevel
        OpEventSetActiveDiagnostic_SetActiveDiagnostic_DCMServices: start-on-event=SetActiveDiagnostic, operation=DCMServices.SetActiveDiagnostic
        OpEventGetRequestKind_GetRequestKind_DCMServices: start-on-event=GetRequestKind, operation=DCMServices.GetRequestKind
      port-api-options:
        enable-take-address=true, indirect-api=false, port=DcmControlDtcSetting
        enable-take-address=true, indirect-api=false, port=DcmEcuReset
        enable-take-address=true, indirect-api=false, port=DcmDiagnosticSessionControl
        enable-take-address=true, indirect-api=false, port=DCMServices
        enable-take-address=true, indirect-api=false, port=SecurityAccess_UnlockedL1
        enable-take-address=true, indirect-api=false, port=RoutineServices_HUT_self_check
        enable-take-address=true, indirect-api=false, port=DataServices_Vehicle_Speed_D001_Vehicle_Speed
        enable-take-address=true, indirect-api=false, port=DataServices_Telematics_Module_Status_E01A_Telematics_Module_Status
        enable-take-address=true, indirect-api=false, port=DataServices_Wi_Fi_Module_Status_E013_Wi_Fi_Module_Status
        enable-take-address=true, indirect-api=false, port=DataServices_BT_firmware_version_E009_BT_firmware_version
        enable-take-address=true, indirect-api=false, port=DataServices_BT_active_profile_list_E008_BT_active_profile_list
        enable-take-address=true, indirect-api=false, port=DataServices_Vehicle_Identification_Number_F190_VIN
        enable-take-address=true, indirect-api=false, port=DataServices_AME_Read_SW_and_HW_Version_FD04_CombinedDataElement
        enable-take-address=true, indirect-api=false, port=DataServices_AME_Skip_welcome_confirm_FD20_Reserved_Byte
        enable-take-address=true, indirect-api=false, port=DataServices_Select_Speaker_Test_Tone_FD34_Select_tone
        enable-take-address=true, indirect-api=false, port=DataServices_AME_Read_GPS_Info_FD72_Number_of_used_satellite
        enable-take-address=true, indirect-api=false, port=DataServices_AME_Read_GPS_Info_FD72_Number_of_visible_staellite
        enable-take-address=true, indirect-api=false, port=DataServices_AME_Read_GPS_Info_FD72_Number_of_fix
        enable-take-address=true, indirect-api=false, port=DataServices_AME_Set_AM_Frequency_FD52_AM_Frequency
        enable-take-address=true, indirect-api=false, port=DataServices_AME_Power_Control_FD01_Power_Control
        enable-take-address=true, indirect-api=false, port=DataServices_AME_Set_Mute_Control_FD31_Set_Mute_Control
        enable-take-address=true, indirect-api=false, port=DataServices_AME_Set_Volume_FD30_Set_Volume
        enable-take-address=true, indirect-api=false, port=DataServices_Audio_jack_status_E00A_Audio_jack_status
        enable-take-address=true, indirect-api=false, port=DataServices_AME_ReadGPSSNR_FD73_GPSSNR
        enable-take-address=true, indirect-api=false, port=DataServices_Support_FM_frequency_Min_E00F_Support_FM_frequency_Min
        enable-take-address=true, indirect-api=false, port=DataServices_Support_FM_frequency_Max_E010_Support_FM_frequency_Max
        enable-take-address=true, indirect-api=false, port=DataServices_Number_of_installed_cameras_E001_Number_of_installed_cameras
        enable-take-address=true, indirect-api=false, port=DataServices_AME_Write_harman_manufactory_part_number_FD07_Harman_Manufactory_Part_Number
        enable-take-address=true, indirect-api=false, port=DataServices_AME_Read_system_temperature_FD13_CombinedDataElement
        enable-take-address=true, indirect-api=false, port=DataServices_AME_Set_FAN_speed_FD12_FAN_Speed
        enable-take-address=true, indirect-api=false, port=DataServices_System_Supplier_Identifier_F18A_System_Supplier_Identifier
        enable-take-address=true, indirect-api=false, port=DataServices_AME_Route_MIC_To_Internal_Speaker_FD36_Control
        enable-take-address=true, indirect-api=false, port=DataServices_AME_Route_MIC_To_Internal_Speaker_FD36_Mic
        enable-take-address=true, indirect-api=false, port=DataServices_Currently_connected_USB_Type_E00C_Currently_connected_USB_Type
        enable-take-address=true, indirect-api=false, port=DataServices_Bluetooth_Status_E006_Bluetooth_Status
        enable-take-address=true, indirect-api=false, port=DataServices_AME_Select_Audio_Buffer_Channel_Output_FD39_SelectAudioBufferChannelOutput
        enable-take-address=true, indirect-api=false, port=DataServices_AME_Route_Video_To_HMI_FD37_Route_Vedio_To_HMI
        enable-take-address=true, indirect-api=false, port=DataServices_FM_signal_Strength_E012_FM_signal_Strength
        enable-take-address=true, indirect-api=false, port=DataServices_AME_Switch_Source_FD40_SelectAudioBufferChannelOutput
        enable-take-address=true, indirect-api=false, port=DataServices_AME_Mirror_Link_connection_FD6D_Mirror_Link_connection
        enable-take-address=true, indirect-api=false, port=DataServices_AME_BT_Auto_Pairing_FD63_BT_Chip
        enable-take-address=true, indirect-api=false, port=DataServices_AME_BT_Auto_Pairing_FD63_BT_MAC_Address
        enable-take-address=true, indirect-api=false, port=DataServices_Odometer_D004_Odometer
        enable-take-address=true, indirect-api=false, port=DataServices_Wi_Fi_Module_Hardware_Part_Number_E015_Wi_Fi_Module_Hardware_Part_Number
        enable-take-address=true, indirect-api=false, port=DataServices_AME_Display_Color_Bar_Control_FD38_Display_Color_Bar_Control
        enable-take-address=true, indirect-api=false, port=DataServices_AME_Enter_NAV_Demo_Mode_FD70_Demo_Mode
        enable-take-address=true, indirect-api=false, port=DataServices_Support_AM_frequency_Min_E00D_Support_AM_frequency_Min
        enable-take-address=true, indirect-api=false, port=DataServices_Bluetooth_Current_Discoverability_modes_E005_Bluetooth_Current_Discoverability_modes
        enable-take-address=true, indirect-api=false, port=DataServices_Number_of_external_USB_devices_plugged_E00B_Number_of_external_USB_devices_plugged
        enable-take-address=true, indirect-api=false, port=DataServices_AME_Set_WIFI_Mode_FD67_WiFi_Mode
        enable-take-address=true, indirect-api=false, port=DataServices_Support_AM_frequency_Max_E00E_Support_AM_frequency_Max
        enable-take-address=true, indirect-api=false, port=DataServices_Vehicle_Manufacture_Spare_Part_Number_F187_Vehicle_Manufacture_Spare_Part_Number
        enable-take-address=true, indirect-api=false, port=DataServices_AME_BT_Handfree_Loopback_Test_FD6B_Reserved_Byte
        enable-take-address=true, indirect-api=false, port=DataServices_AME_TrackMedia_Audio_Source_Play_FD41_TrackMedia_AudioSourcePlay
        enable-take-address=true, indirect-api=false, port=DataServices_BT_Power_Class_E007_BT_Power_Class
        enable-take-address=true, indirect-api=false, port=DataServices_AME_Set_FM_Frequency_FD50_FM_Frequency
        enable-take-address=true, indirect-api=false, port=DataServices_Set_debug_on_off_control_FDF0_CombinedDataElement
        enable-take-address=true, indirect-api=false, port=DataServices_ECU_Serial_Number_F18C_ECU_Serial_Number
        enable-take-address=true, indirect-api=false, port=DataServices_System_Supplier_ECU_Hardware_Version_Number_F193_Hardware_Version_Number
        enable-take-address=true, indirect-api=false, port=DataServices_System_Supplier_ECU_Software_Version_Number_F195_Software_Version_Number
        enable-take-address=true, indirect-api=false, port=DataServices_Operating_Voltage_Value_D003_Operating_Voltage_Value
        enable-take-address=true, indirect-api=false, port=DataServices_AME_TBOX_communication_status_check_FD80_TBOX_status
        enable-take-address=true, indirect-api=false, port=DataServices_AME_Read_harman_manufactory_part_number_FD06_Harman_Manufactory_Part_Number
        enable-take-address=true, indirect-api=false, port=DataServices_AME_Read_FAN_speed_FD11_FAN_Speed
        enable-take-address=true, indirect-api=false, port=DataServices_AME_Read_Head_Unit_Connector_Status_FD90_CombinedDataElement
        enable-take-address=true, indirect-api=false, port=DataServices_Number_of_installed_speakers_E01C_Number_of_installed_speakers
        enable-take-address=true, indirect-api=false, port=DataServices_Tbox_Gateway_sub_mask_E017_Tbox_Gateway_sub_mask
        enable-take-address=true, indirect-api=false, port=DataServices_AME_Set_External_Output_Status_FD93_HW
        enable-take-address=true, indirect-api=false, port=DataServices_AME_Set_External_Output_Status_FD93_Status
        enable-take-address=true, indirect-api=false, port=DataServices_Present_GPS_coordinates_shift_data_E003_GPS_coordinates
        enable-take-address=true, indirect-api=false, port=DataServices_AME_Set_HMI_Language_FD21_Set_HMI_Language
        enable-take-address=true, indirect-api=false, port=DataServices_AME_Connectivy_OnOff_Control_FD62_BT_WiFi
        enable-take-address=true, indirect-api=false, port=DataServices_AME_Connectivy_OnOff_Control_FD62_ON_OFF
        enable-take-address=true, indirect-api=false, port=DataServices_AME_Input_Output_OnOff_control_FD18_OnOffModule
        enable-take-address=true, indirect-api=false, port=DataServices_AME_Input_Output_OnOff_control_FD18_OnOffValue
        enable-take-address=true, indirect-api=false, port=DataServices_AME_Write_MAC_Address_FD61_subID
        enable-take-address=true, indirect-api=false, port=DataServices_AME_Write_MAC_Address_FD61_A{0..5}
        enable-take-address=true, indirect-api=false, port=DataServices_C_matrix_Version_of_the_ECU_product_F1A2_C_matrix_Version
        enable-take-address=true, indirect-api=false, port=DataServices_Switch_HU_boot_mode_FDF1_Boot_Mode
        enable-take-address=true, indirect-api=false, port=DataServices_AME_Read_MAC_Address_FD60_CombinedDataElement
        enable-take-address=true, indirect-api=false, port=DataServices_AME_Read_AME_diagnostic_version_FD08_CombinedDataElement
        enable-take-address=true, indirect-api=false, port=DataServices_VehicleNetworkConfiguration_F1A1_VehicleNetworkConfiguration
        enable-take-address=true, indirect-api=false, port=DataServices_Engine_Speed_D002_Engine_Speed
        enable-take-address=true, indirect-api=false, port=DataServices_Screen_resolution_E002_Height
        enable-take-address=true, indirect-api=false, port=DataServices_Screen_resolution_E002_Width
        enable-take-address=true, indirect-api=false, port=DataServices_AME_Read_system_voltage_FD14_CombinedDataElement
        enable-take-address=true, indirect-api=false, port=DataServices_Tbox_IP_Address_E016_Tbox_IP_Address
        enable-take-address=true, indirect-api=false, port=DataServices_DTC_Occurrence_Timer_D005_Occure_Time_Inforamation
        enable-take-address=true, indirect-api=false, port=DataServices_INVALID_SHORTNAME_AME_Reset_Factory_Mode_FD05_Reset_Factory_Mode
        enable-take-address=true, indirect-api=false, port=DataServices_Tbox_geographical_coordinates_when_connection_lost_E019_Tbox_geographical_coordinates_when_connection_lost
        enable-take-address=true, indirect-api=false, port=DataServices_AME_Read_GYRO_Status_FD71_GYRO_Status
        enable-take-address=true, indirect-api=false, port=DataServices_Wi_Fi_Module_Firmware_Version_E014_Wi_Fi_Module_Firmware_Version
        enable-take-address=true, indirect-api=false, port=DataServices_AME_Select_Speaker_Zone_FD33_Select_Speaker_Zone
        enable-take-address=true, indirect-api=false, port=DataServices_AME_Play_BT_Audio_Control_FD64_Reserved_Byte
        enable-take-address=true, indirect-api=false, port=DataServices_AME_Switch_BIOS_Mode_FD02_Switch_BIOS
        enable-take-address=true, indirect-api=false, port=DataServices_AME_Ethernet_IP_Ping_Function_FD6E_IPAddress_Byte3
        enable-take-address=true, indirect-api=false, port=DataServices_AME_Ethernet_IP_Ping_Function_FD6E_IPAddress_Byte4
        enable-take-address=true, indirect-api=false, port=DataServices_AME_Ethernet_IP_Ping_Function_FD6E_Ethernet_Channel
        enable-take-address=true, indirect-api=false, port=DataServices_AME_Ethernet_IP_Ping_Function_FD6E_IPAddress_Byte1
        enable-take-address=true, indirect-api=false, port=DataServices_AME_Ethernet_IP_Ping_Function_FD6E_IPAddress_Byte2
        enable-take-address=true, indirect-api=false, port=DataServices_AM_signal_Strength_E011_AM_signal_Strength
        enable-take-address=true, indirect-api=false, port=DataServices_Tbox_Last_connection_lost_time_stamp_E018_Tbox_Last_connection_lost_time_stamp
        enable-take-address=true, indirect-api=false, port=DataServices_AME_Read_Detection_Input_Info_FD92_CombinedDataElement
        enable-take-address=true, indirect-api=false, port=DataServices_Data_DID_StartApplication
        enable-take-address=true, indirect-api=false, port=DcmCommunicationControl_ComMConf_ComMChannel_CN_CAN_fe6ecc87
      7 x runnable:
        Dcm_MainFunction
          4 x mode switch point:
            ModeSwitchPointDcm_MainFunction_DcmControlDtcSetting_DcmControlDtcSetting: mode-group=DcmControlDtcSetting.DcmControlDtcSetting
            ModeSwitchPointDcm_MainFunction_DcmEcuReset_DcmEcuReset: mode-group=DcmEcuReset.DcmEcuReset
            ModeSwitchPointDcm_MainFunction_DcmDiagnosticSessionControl_DcmDiagnosticSessionControl: mode-group=DcmDiagnosticSessionControl.DcmDiagnosticSessionControl
            ModeSwitchPointDcm_MainFunction_DcmCommunicationControl_ComMConf_ComMChannel_CN_CAN_fe6ecc87_DcmCommunicationControl_Co_d6d2131a: mode-group=DcmCommunicationControl_ComMConf_ComMChannel_CN_CAN_fe6ecc87.DcmCommunicationControl_ComMConf_ComMChannel_CN_CAN_fe6ecc87
          174 x sync call, all with timeout=0:
            OpServerCallDcm_MainFunction_GetSeed_SecurityAccess_UnlockedL1: operation=SecurityAccess_UnlockedL1.GetSeed
            OpServerCallDcm_MainFunction_CompareKey_SecurityAccess_UnlockedL1: operation=SecurityAccess_UnlockedL1.CompareKey
            OpServerCallDcm_MainFunction_Start_RoutineServices_HUT_self_check: operation=RoutineServices_HUT_self_check.Start
            OpServerCallDcm_MainFunction_Stop_RoutineServices_HUT_self_check: operation=RoutineServices_HUT_self_check.Stop
            OpServerCallDcm_MainFunction_RequestResults_RoutineServices_HUT_self_check: operation=RoutineServices_HUT_self_check.RequestResults
            OpServerCallDcm_MainFunction_ReadData_DataServices_Vehicle_Speed_D001_Vehicle_Speed: operation=DataServices_Vehicle_Speed_D001_Vehicle_Speed.ReadData
            OpServerCallDcm_MainFunction_ConditionCheckRead_DataServices_Vehicle_Speed_D001_Vehicle_Speed: operation=DataServices_Vehicle_Speed_D001_Vehicle_Speed.ConditionCheckRead
            OpServerCallDcm_MainFunction_ReadData_DataServices_Telematics_Module_Status_E01A_Telematics_Module_Status: operation=DataServices_Telematics_Module_Status_E01A_Telematics_Module_Status.ReadData
            OpServerCallDcm_MainFunction_ConditionCheckRead_DataServices_Telematics_Module_Status_E01A_Telematics_Module_Status: operation=DataServices_Telematics_Module_Status_E01A_Telematics_Module_Status.ConditionCheckRead
            OpServerCallDcm_MainFunction_ReadData_DataServices_Wi_Fi_Module_Status_E013_Wi_Fi_Module_Status: operation=DataServices_Wi_Fi_Module_Status_E013_Wi_Fi_Module_Status.ReadData
            OpServerCallDcm_MainFunction_ConditionCheckRead_DataServices_Wi_Fi_Module_Status_E013_Wi_Fi_Module_Status: operation=DataServices_Wi_Fi_Module_Status_E013_Wi_Fi_Module_Status.ConditionCheckRead
            OpServerCallDcm_MainFunction_ReadData_DataServices_BT_firmware_version_E009_BT_firmware_version: operation=DataServices_BT_firmware_version_E009_BT_firmware_version.ReadData
            OpServerCallDcm_MainFunction_ConditionCheckRead_DataServices_BT_firmware_version_E009_BT_firmware_version: operation=DataServices_BT_firmware_version_E009_BT_firmware_version.ConditionCheckRead
            OpServerCallDcm_MainFunction_ReadData_DataServices_BT_active_profile_list_E008_BT_active_profile_list: operation=DataServices_BT_active_profile_list_E008_BT_active_profile_list.ReadData
            OpServerCallDcm_MainFunction_ConditionCheckRead_DataServices_BT_active_profile_list_E008_BT_active_profile_list: operation=DataServices_BT_active_profile_list_E008_BT_active_profile_list.ConditionCheckRead
            OpServerCallDcm_MainFunction_ReadData_DataServices_Vehicle_Identification_Number_F190_VIN: operation=DataServices_Vehicle_Identification_Number_F190_VIN.ReadData
            OpServerCallDcm_MainFunction_ConditionCheckRead_DataServices_Vehicle_Identification_Number_F190_VIN: operation=DataServices_Vehicle_Identification_Number_F190_VIN.ConditionCheckRead
            OpServerCallDcm_MainFunction_WriteData_DataServices_Vehicle_Identification_Number_F190_VIN: operation=DataServices_Vehicle_Identification_Number_F190_VIN.WriteData
            OpServerCallDcm_MainFunction_ReadData_DataServices_AME_Read_SW_and_HW_Version_FD04_CombinedDataElement: operation=DataServices_AME_Read_SW_and_HW_Version_FD04_CombinedDataElement.ReadData
            OpServerCallDcm_MainFunction_ReadDataLength_DataServices_AME_Read_SW_and_HW_Version_FD04_CombinedDataElement: operation=DataServices_AME_Read_SW_and_HW_Version_FD04_CombinedDataElement.ReadDataLength
            OpServerCallDcm_MainFunction_ConditionCheckRead_DataServices_AME_Read_SW_and_HW_Version_FD04_CombinedDataElement: operation=DataServices_AME_Read_SW_and_HW_Version_FD04_CombinedDataElement.ConditionCheckRead
            OpServerCallDcm_MainFunction_WriteData_DataServices_AME_Skip_welcome_confirm_FD20_Reserved_Byte: operation=DataServices_AME_Skip_welcome_confirm_FD20_Reserved_Byte.WriteData
            OpServerCallDcm_MainFunction_WriteData_DataServices_Select_Speaker_Test_Tone_FD34_Select_tone: operation=DataServices_Select_Speaker_Test_Tone_FD34_Select_tone.WriteData
            OpServerCallDcm_MainFunction_ReadData_DataServices_AME_Read_GPS_Info_FD72_Number_of_used_satellite: operation=DataServices_AME_Read_GPS_Info_FD72_Number_of_used_satellite.ReadData
            OpServerCallDcm_MainFunction_ConditionCheckRead_DataServices_AME_Read_GPS_Info_FD72_Number_of_used_satellite: operation=DataServices_AME_Read_GPS_Info_FD72_Number_of_used_satellite.ConditionCheckRead
            OpServerCallDcm_MainFunction_ReadData_DataServices_AME_Read_GPS_Info_FD72_Number_of_visible_staellite: operation=DataServices_AME_Read_GPS_Info_FD72_Number_of_visible_staellite.ReadData
            OpServerCallDcm_MainFunction_ConditionCheckRead_DataServices_AME_Read_GPS_Info_FD72_Number_of_visible_staellite: operation=DataServices_AME_Read_GPS_Info_FD72_Number_of_visible_staellite.ConditionCheckRead
            OpServerCallDcm_MainFunction_ReadData_DataServices_AME_Read_GPS_Info_FD72_Number_of_fix: operation=DataServices_AME_Read_GPS_Info_FD72_Number_of_fix.ReadData
            OpServerCallDcm_MainFunction_ConditionCheckRead_DataServices_AME_Read_GPS_Info_FD72_Number_of_fix: operation=DataServices_AME_Read_GPS_Info_FD72_Number_of_fix.ConditionCheckRead
            OpServerCallDcm_MainFunction_WriteData_DataServices_AME_Set_AM_Frequency_FD52_AM_Frequency: operation=DataServices_AME_Set_AM_Frequency_FD52_AM_Frequency.WriteData
            OpServerCallDcm_MainFunction_WriteData_DataServices_AME_Power_Control_FD01_Power_Control: operation=DataServices_AME_Power_Control_FD01_Power_Control.WriteData
            OpServerCallDcm_MainFunction_WriteData_DataServices_AME_Set_Mute_Control_FD31_Set_Mute_Control: operation=DataServices_AME_Set_Mute_Control_FD31_Set_Mute_Control.WriteData
            OpServerCallDcm_MainFunction_WriteData_DataServices_AME_Set_Volume_FD30_Set_Volume: operation=DataServices_AME_Set_Volume_FD30_Set_Volume.WriteData
            OpServerCallDcm_MainFunction_ReadData_DataServices_Audio_jack_status_E00A_Audio_jack_status: operation=DataServices_Audio_jack_status_E00A_Audio_jack_status.ReadData
            OpServerCallDcm_MainFunction_ConditionCheckRead_DataServices_Audio_jack_status_E00A_Audio_jack_status: operation=DataServices_Audio_jack_status_E00A_Audio_jack_status.ConditionCheckRead
            OpServerCallDcm_MainFunction_ReadData_DataServices_AME_ReadGPSSNR_FD73_GPSSNR: operation=DataServices_AME_ReadGPSSNR_FD73_GPSSNR.ReadData
            OpServerCallDcm_MainFunction_ConditionCheckRead_DataServices_AME_ReadGPSSNR_FD73_GPSSNR: operation=DataServices_AME_ReadGPSSNR_FD73_GPSSNR.ConditionCheckRead
            OpServerCallDcm_MainFunction_ReadData_DataServices_Support_FM_frequency_Min_E00F_Support_FM_frequency_Min: operation=DataServices_Support_FM_frequency_Min_E00F_Support_FM_frequency_Min.ReadData
            OpServerCallDcm_MainFunction_ConditionCheckRead_DataServices_Support_FM_frequency_Min_E00F_Support_FM_frequency_Min: operation=DataServices_Support_FM_frequency_Min_E00F_Support_FM_frequency_Min.ConditionCheckRead
            OpServerCallDcm_MainFunction_ReadData_DataServices_Support_FM_frequency_Max_E010_Support_FM_frequency_Max: operation=DataServices_Support_FM_frequency_Max_E010_Support_FM_frequency_Max.ReadData
            OpServerCallDcm_MainFunction_ConditionCheckRead_DataServices_Support_FM_frequency_Max_E010_Support_FM_frequency_Max: operation=DataServices_Support_FM_frequency_Max_E010_Support_FM_frequency_Max.ConditionCheckRead
            OpServerCallDcm_MainFunction_ReadData_DataServices_Number_of_installed_cameras_E001_Number_of_installed_cameras: operation=DataServices_Number_of_installed_cameras_E001_Number_of_installed_cameras.ReadData
            OpServerCallDcm_MainFunction_ConditionCheckRead_DataServices_Number_of_installed_cameras_E001_Number_of_installed_cameras: operation=DataServices_Number_of_installed_cameras_E001_Number_of_installed_cameras.ConditionCheckRead
            OpServerCallDcm_MainFunction_WriteData_DataServices_AME_Write_harman_manufactory_part_number_FD07_Harman_Manufactory_Part_Number: operation=DataServices_AME_Write_harman_manufactory_part_number_FD07_Harman_Manufactory_Part_Number.WriteData
            OpServerCallDcm_MainFunction_ReadData_DataServices_AME_Read_system_temperature_FD13_CombinedDataElement: operation=DataServices_AME_Read_system_temperature_FD13_CombinedDataElement.ReadData
            OpServerCallDcm_MainFunction_ConditionCheckRead_DataServices_AME_Read_system_temperature_FD13_CombinedDataElement: operation=DataServices_AME_Read_system_temperature_FD13_CombinedDataElement.ConditionCheckRead
            OpServerCallDcm_MainFunction_WriteData_DataServices_AME_Set_FAN_speed_FD12_FAN_Speed: operation=DataServices_AME_Set_FAN_speed_FD12_FAN_Speed.WriteData
            OpServerCallDcm_MainFunction_ReadData_DataServices_System_Supplier_Identifier_F18A_System_Supplier_Identifier: operation=DataServices_System_Supplier_Identifier_F18A_System_Supplier_Identifier.ReadData
            OpServerCallDcm_MainFunction_ConditionCheckRead_DataServices_System_Supplier_Identifier_F18A_System_Supplier_Identifier: operation=DataServices_System_Supplier_Identifier_F18A_System_Supplier_Identifier.ConditionCheckRead
            OpServerCallDcm_MainFunction_WriteData_DataServices_AME_Route_MIC_To_Internal_Speaker_FD36_Control: operation=DataServices_AME_Route_MIC_To_Internal_Speaker_FD36_Control.WriteData
            OpServerCallDcm_MainFunction_WriteData_DataServices_AME_Route_MIC_To_Internal_Speaker_FD36_Mic: operation=DataServices_AME_Route_MIC_To_Internal_Speaker_FD36_Mic.WriteData
            OpServerCallDcm_MainFunction_ReadData_DataServices_Currently_connected_USB_Type_E00C_Currently_connected_USB_Type: operation=DataServices_Currently_connected_USB_Type_E00C_Currently_connected_USB_Type.ReadData
            OpServerCallDcm_MainFunction_ConditionCheckRead_DataServices_Currently_connected_USB_Type_E00C_Currently_connected_USB_Type: operation=DataServices_Currently_connected_USB_Type_E00C_Currently_connected_USB_Type.ConditionCheckRead
            OpServerCallDcm_MainFunction_ReadData_DataServices_Bluetooth_Status_E006_Bluetooth_Status: operation=DataServices_Bluetooth_Status_E006_Bluetooth_Status.ReadData
            OpServerCallDcm_MainFunction_ConditionCheckRead_DataServices_Bluetooth_Status_E006_Bluetooth_Status: operation=DataServices_Bluetooth_Status_E006_Bluetooth_Status.ConditionCheckRead
            OpServerCallDcm_MainFunction_WriteData_DataServices_AME_Select_Audio_Buffer_Channel_Output_FD39_SelectAudioBufferChannelOutput: operation=DataServices_AME_Select_Audio_Buffer_Channel_Output_FD39_SelectAudioBufferChannelOutput.WriteData
            OpServerCallDcm_MainFunction_WriteData_DataServices_AME_Route_Video_To_HMI_FD37_Route_Vedio_To_HMI: operation=DataServices_AME_Route_Video_To_HMI_FD37_Route_Vedio_To_HMI.WriteData
            OpServerCallDcm_MainFunction_ReadData_DataServices_FM_signal_Strength_E012_FM_signal_Strength: operation=DataServices_FM_signal_Strength_E012_FM_signal_Strength.ReadData
            OpServerCallDcm_MainFunction_ConditionCheckRead_DataServices_FM_signal_Strength_E012_FM_signal_Strength: operation=DataServices_FM_signal_Strength_E012_FM_signal_Strength.ConditionCheckRead
            OpServerCallDcm_MainFunction_WriteData_DataServices_AME_Switch_Source_FD40_SelectAudioBufferChannelOutput: operation=DataServices_AME_Switch_Source_FD40_SelectAudioBufferChannelOutput.WriteData
            OpServerCallDcm_MainFunction_WriteData_DataServices_AME_Mirror_Link_connection_FD6D_Mirror_Link_connection: operation=DataServices_AME_Mirror_Link_connection_FD6D_Mirror_Link_connection.WriteData
            OpServerCallDcm_MainFunction_WriteData_DataServices_AME_BT_Auto_Pairing_FD63_BT_Chip: operation=DataServices_AME_BT_Auto_Pairing_FD63_BT_Chip.WriteData
            OpServerCallDcm_MainFunction_WriteData_DataServices_AME_BT_Auto_Pairing_FD63_BT_MAC_Address: operation=DataServices_AME_BT_Auto_Pairing_FD63_BT_MAC_Address.WriteData
            OpServerCallDcm_MainFunction_ReadData_DataServices_Odometer_D004_Odometer: operation=DataServices_Odometer_D004_Odometer.ReadData
            OpServerCallDcm_MainFunction_ConditionCheckRead_DataServices_Odometer_D004_Odometer: operation=DataServices_Odometer_D004_Odometer.ConditionCheckRead
            OpServerCallDcm_MainFunction_ReadData_DataServices_Wi_Fi_Module_Hardware_Part_Number_E015_Wi_Fi_Module_Hardware_Part_Number: operation=DataServices_Wi_Fi_Module_Hardware_Part_Number_E015_Wi_Fi_Module_Hardware_Part_Number.ReadData
            OpServerCallDcm_MainFunction_ConditionCheckRead_DataServices_Wi_Fi_Module_Hardware_Part_Number_E015_Wi_Fi_Module_Hardwa_53560f57: operation=DataServices_Wi_Fi_Module_Hardware_Part_Number_E015_Wi_Fi_Module_Hardware_Part_Number.ConditionCheckRead
            OpServerCallDcm_MainFunction_WriteData_DataServices_AME_Display_Color_Bar_Control_FD38_Display_Color_Bar_Control: operation=DataServices_AME_Display_Color_Bar_Control_FD38_Display_Color_Bar_Control.WriteData
            OpServerCallDcm_MainFunction_WriteData_DataServices_AME_Enter_NAV_Demo_Mode_FD70_Demo_Mode: operation=DataServices_AME_Enter_NAV_Demo_Mode_FD70_Demo_Mode.WriteData
            OpServerCallDcm_MainFunction_ReadData_DataServices_Support_AM_frequency_Min_E00D_Support_AM_frequency_Min: operation=DataServices_Support_AM_frequency_Min_E00D_Support_AM_frequency_Min.ReadData
            OpServerCallDcm_MainFunction_ConditionCheckRead_DataServices_Support_AM_frequency_Min_E00D_Support_AM_frequency_Min: operation=DataServices_Support_AM_frequency_Min_E00D_Support_AM_frequency_Min.ConditionCheckRead
            OpServerCallDcm_MainFunction_ReadData_DataServices_Bluetooth_Current_Discoverability_modes_E005_Bluetooth_Current_Disco_d4085942: operation=DataServices_Bluetooth_Current_Discoverability_modes_E005_Bluetooth_Current_Discoverability_modes.ReadData
            OpServerCallDcm_MainFunction_ConditionCheckRead_DataServices_Bluetooth_Current_Discoverability_modes_E005_Bluetooth_Cur_f0df259b: operation=DataServices_Bluetooth_Current_Discoverability_modes_E005_Bluetooth_Current_Discoverability_modes.ConditionCheckRead
            OpServerCallDcm_MainFunction_ReadData_DataServices_Number_of_external_USB_devices_plugged_E00B_Number_of_external_USB_d_bb42ba51: operation=DataServices_Number_of_external_USB_devices_plugged_E00B_Number_of_external_USB_devices_plugged.ReadData
            OpServerCallDcm_MainFunction_ConditionCheckRead_DataServices_Number_of_external_USB_devices_plugged_E00B_Number_of_exte_6251904c: operation=DataServices_Number_of_external_USB_devices_plugged_E00B_Number_of_external_USB_devices_plugged.ConditionCheckRead
            OpServerCallDcm_MainFunction_WriteData_DataServices_AME_Set_WIFI_Mode_FD67_WiFi_Mode: operation=DataServices_AME_Set_WIFI_Mode_FD67_WiFi_Mode.WriteData
            OpServerCallDcm_MainFunction_ReadData_DataServices_Support_AM_frequency_Max_E00E_Support_AM_frequency_Max: operation=DataServices_Support_AM_frequency_Max_E00E_Support_AM_frequency_Max.ReadData
            OpServerCallDcm_MainFunction_ConditionCheckRead_DataServices_Support_AM_frequency_Max_E00E_Support_AM_frequency_Max: operation=DataServices_Support_AM_frequency_Max_E00E_Support_AM_frequency_Max.ConditionCheckRead
            OpServerCallDcm_MainFunction_ReadData_DataServices_Vehicle_Manufacture_Spare_Part_Number_F187_Vehicle_Manufacture_Spare_273f7f72: operation=DataServices_Vehicle_Manufacture_Spare_Part_Number_F187_Vehicle_Manufacture_Spare_Part_Number.ReadData
            OpServerCallDcm_MainFunction_ConditionCheckRead_DataServices_Vehicle_Manufacture_Spare_Part_Number_F187_Vehicle_Manufac_edc528ca: operation=DataServices_Vehicle_Manufacture_Spare_Part_Number_F187_Vehicle_Manufacture_Spare_Part_Number.ConditionCheckRead
            OpServerCallDcm_MainFunction_WriteData_DataServices_AME_BT_Handfree_Loopback_Test_FD6B_Reserved_Byte: operation=DataServices_AME_BT_Handfree_Loopback_Test_FD6B_Reserved_Byte.WriteData
            OpServerCallDcm_MainFunction_WriteData_DataServices_AME_TrackMedia_Audio_Source_Play_FD41_TrackMedia_AudioSourcePlay: operation=DataServices_AME_TrackMedia_Audio_Source_Play_FD41_TrackMedia_AudioSourcePlay.WriteData
            OpServerCallDcm_MainFunction_ReadData_DataServices_BT_Power_Class_E007_BT_Power_Class: operation=DataServices_BT_Power_Class_E007_BT_Power_Class.ReadData
            OpServerCallDcm_MainFunction_ConditionCheckRead_DataServices_BT_Power_Class_E007_BT_Power_Class: operation=DataServices_BT_Power_Class_E007_BT_Power_Class.ConditionCheckRead
            OpServerCallDcm_MainFunction_WriteData_DataServices_AME_Set_FM_Frequency_FD50_FM_Frequency: operation=DataServices_AME_Set_FM_Frequency_FD50_FM_Frequency.WriteData
            OpServerCallDcm_MainFunction_ReadData_DataServices_Set_debug_on_off_control_FDF0_CombinedDataElement: operation=DataServices_Set_debug_on_off_control_FDF0_CombinedDataElement.ReadData
            OpServerCallDcm_MainFunction_ReadDataLength_DataServices_Set_debug_on_off_control_FDF0_CombinedDataElement: operation=DataServices_Set_debug_on_off_control_FDF0_CombinedDataElement.ReadDataLength
            OpServerCallDcm_MainFunction_ConditionCheckRead_DataServices_Set_debug_on_off_control_FDF0_CombinedDataElement: operation=DataServices_Set_debug_on_off_control_FDF0_CombinedDataElement.ConditionCheckRead
            OpServerCallDcm_MainFunction_WriteData_DataServices_Set_debug_on_off_control_FDF0_CombinedDataElement: operation=DataServices_Set_debug_on_off_control_FDF0_CombinedDataElement.WriteData
            OpServerCallDcm_MainFunction_ReadData_DataServices_ECU_Serial_Number_F18C_ECU_Serial_Number: operation=DataServices_ECU_Serial_Number_F18C_ECU_Serial_Number.ReadData
            OpServerCallDcm_MainFunction_ConditionCheckRead_DataServices_ECU_Serial_Number_F18C_ECU_Serial_Number: operation=DataServices_ECU_Serial_Number_F18C_ECU_Serial_Number.ConditionCheckRead
            OpServerCallDcm_MainFunction_WriteData_DataServices_ECU_Serial_Number_F18C_ECU_Serial_Number: operation=DataServices_ECU_Serial_Number_F18C_ECU_Serial_Number.WriteData
            OpServerCallDcm_MainFunction_ReadData_DataServices_System_Supplier_ECU_Hardware_Version_Number_F193_Hardware_Version_Number: operation=DataServices_System_Supplier_ECU_Hardware_Version_Number_F193_Hardware_Version_Number.ReadData
            OpServerCallDcm_MainFunction_ConditionCheckRead_DataServices_System_Supplier_ECU_Hardware_Version_Number_F193_Hardware_9c656d62: operation=DataServices_System_Supplier_ECU_Hardware_Version_Number_F193_Hardware_Version_Number.ConditionCheckRead
            OpServerCallDcm_MainFunction_ReadData_DataServices_System_Supplier_ECU_Software_Version_Number_F195_Software_Version_Number: operation=DataServices_System_Supplier_ECU_Software_Version_Number_F195_Software_Version_Number.ReadData
            OpServerCallDcm_MainFunction_ConditionCheckRead_DataServices_System_Supplier_ECU_Software_Version_Number_F195_Software_67c0a85a: operation=DataServices_System_Supplier_ECU_Software_Version_Number_F195_Software_Version_Number.ConditionCheckRead
            OpServerCallDcm_MainFunction_ReadData_DataServices_Operating_Voltage_Value_D003_Operating_Voltage_Value: operation=DataServices_Operating_Voltage_Value_D003_Operating_Voltage_Value.ReadData
            OpServerCallDcm_MainFunction_ConditionCheckRead_DataServices_Operating_Voltage_Value_D003_Operating_Voltage_Value: operation=DataServices_Operating_Voltage_Value_D003_Operating_Voltage_Value.ConditionCheckRead
            OpServerCallDcm_MainFunction_ReadData_DataServices_AME_TBOX_communication_status_check_FD80_TBOX_status: operation=DataServices_AME_TBOX_communication_status_check_FD80_TBOX_status.ReadData
            OpServerCallDcm_MainFunction_ConditionCheckRead_DataServices_AME_TBOX_communication_status_check_FD80_TBOX_status: operation=DataServices_AME_TBOX_communication_status_check_FD80_TBOX_status.ConditionCheckRead
            OpServerCallDcm_MainFunction_ReadData_DataServices_AME_Read_harman_manufactory_part_number_FD06_Harman_Manufactory_Part_Number: operation=DataServices_AME_Read_harman_manufactory_part_number_FD06_Harman_Manufactory_Part_Number.ReadData
            OpServerCallDcm_MainFunction_ConditionCheckRead_DataServices_AME_Read_harman_manufactory_part_number_FD06_Harman_Manufa_aefd994d: operation=DataServices_AME_Read_harman_manufactory_part_number_FD06_Harman_Manufactory_Part_Number.ConditionCheckRead
            OpServerCallDcm_MainFunction_ReadData_DataServices_AME_Read_FAN_speed_FD11_FAN_Speed: operation=DataServices_AME_Read_FAN_speed_FD11_FAN_Speed.ReadData
            OpServerCallDcm_MainFunction_ConditionCheckRead_DataServices_AME_Read_FAN_speed_FD11_FAN_Speed: operation=DataServices_AME_Read_FAN_speed_FD11_FAN_Speed.ConditionCheckRead
            OpServerCallDcm_MainFunction_ReadData_DataServices_AME_Read_Head_Unit_Connector_Status_FD90_CombinedDataElement: operation=DataServices_AME_Read_Head_Unit_Connector_Status_FD90_CombinedDataElement.ReadData
            OpServerCallDcm_MainFunction_ConditionCheckRead_DataServices_AME_Read_Head_Unit_Connector_Status_FD90_CombinedDataElement: operation=DataServices_AME_Read_Head_Unit_Connector_Status_FD90_CombinedDataElement.ConditionCheckRead
            OpServerCallDcm_MainFunction_ReadData_DataServices_Number_of_installed_speakers_E01C_Number_of_installed_speakers: operation=DataServices_Number_of_installed_speakers_E01C_Number_of_installed_speakers.ReadData
            OpServerCallDcm_MainFunction_ConditionCheckRead_DataServices_Number_of_installed_speakers_E01C_Number_of_installed_speakers: operation=DataServices_Number_of_installed_speakers_E01C_Number_of_installed_speakers.ConditionCheckRead
            OpServerCallDcm_MainFunction_ReadData_DataServices_Tbox_Gateway_sub_mask_E017_Tbox_Gateway_sub_mask: operation=DataServices_Tbox_Gateway_sub_mask_E017_Tbox_Gateway_sub_mask.ReadData
            OpServerCallDcm_MainFunction_ConditionCheckRead_DataServices_Tbox_Gateway_sub_mask_E017_Tbox_Gateway_sub_mask: operation=DataServices_Tbox_Gateway_sub_mask_E017_Tbox_Gateway_sub_mask.ConditionCheckRead
            OpServerCallDcm_MainFunction_WriteData_DataServices_AME_Set_External_Output_Status_FD93_HW: operation=DataServices_AME_Set_External_Output_Status_FD93_HW.WriteData
            OpServerCallDcm_MainFunction_WriteData_DataServices_AME_Set_External_Output_Status_FD93_Status: operation=DataServices_AME_Set_External_Output_Status_FD93_Status.WriteData
            OpServerCallDcm_MainFunction_ReadData_DataServices_Present_GPS_coordinates_shift_data_E003_GPS_coordinates: operation=DataServices_Present_GPS_coordinates_shift_data_E003_GPS_coordinates.ReadData
            OpServerCallDcm_MainFunction_ConditionCheckRead_DataServices_Present_GPS_coordinates_shift_data_E003_GPS_coordinates: operation=DataServices_Present_GPS_coordinates_shift_data_E003_GPS_coordinates.ConditionCheckRead
            OpServerCallDcm_MainFunction_WriteData_DataServices_AME_Set_HMI_Language_FD21_Set_HMI_Language: operation=DataServices_AME_Set_HMI_Language_FD21_Set_HMI_Language.WriteData
            OpServerCallDcm_MainFunction_WriteData_DataServices_AME_Connectivy_OnOff_Control_FD62_BT_WiFi: operation=DataServices_AME_Connectivy_OnOff_Control_FD62_BT_WiFi.WriteData
            OpServerCallDcm_MainFunction_WriteData_DataServices_AME_Connectivy_OnOff_Control_FD62_ON_OFF: operation=DataServices_AME_Connectivy_OnOff_Control_FD62_ON_OFF.WriteData
            OpServerCallDcm_MainFunction_WriteData_DataServices_AME_Input_Output_OnOff_control_FD18_OnOffModule: operation=DataServices_AME_Input_Output_OnOff_control_FD18_OnOffModule.WriteData
            OpServerCallDcm_MainFunction_WriteData_DataServices_AME_Input_Output_OnOff_control_FD18_OnOffValue: operation=DataServices_AME_Input_Output_OnOff_control_FD18_OnOffValue.WriteData
            OpServerCallDcm_MainFunction_WriteData_DataServices_AME_Write_MAC_Address_FD61_subID: operation=DataServices_AME_Write_MAC_Address_FD61_subID.WriteData
            OpServerCallDcm_MainFunction_WriteData_DataServices_AME_Write_MAC_Address_FD61_A{0..5}: operation=DataServices_AME_Write_MAC_Address_FD61_A{0..5}.WriteData
            OpServerCallDcm_MainFunction_ReadData_DataServices_C_matrix_Version_of_the_ECU_product_F1A2_C_matrix_Version: operation=DataServices_C_matrix_Version_of_the_ECU_product_F1A2_C_matrix_Version.ReadData
            OpServerCallDcm_MainFunction_ConditionCheckRead_DataServices_C_matrix_Version_of_the_ECU_product_F1A2_C_matrix_Version: operation=DataServices_C_matrix_Version_of_the_ECU_product_F1A2_C_matrix_Version.ConditionCheckRead
            OpServerCallDcm_MainFunction_WriteData_DataServices_Switch_HU_boot_mode_FDF1_Boot_Mode: operation=DataServices_Switch_HU_boot_mode_FDF1_Boot_Mode.WriteData
            OpServerCallDcm_MainFunction_ReadData_DataServices_AME_Read_MAC_Address_FD60_CombinedDataElement: operation=DataServices_AME_Read_MAC_Address_FD60_CombinedDataElement.ReadData
            OpServerCallDcm_MainFunction_ReadDataLength_DataServices_AME_Read_MAC_Address_FD60_CombinedDataElement: operation=DataServices_AME_Read_MAC_Address_FD60_CombinedDataElement.ReadDataLength
            OpServerCallDcm_MainFunction_ConditionCheckRead_DataServices_AME_Read_MAC_Address_FD60_CombinedDataElement: operation=DataServices_AME_Read_MAC_Address_FD60_CombinedDataElement.ConditionCheckRead
            OpServerCallDcm_MainFunction_ReadData_DataServices_AME_Read_AME_diagnostic_version_FD08_CombinedDataElement: operation=DataServices_AME_Read_AME_diagnostic_version_FD08_CombinedDataElement.ReadData
            OpServerCallDcm_MainFunction_ReadDataLength_DataServices_AME_Read_AME_diagnostic_version_FD08_CombinedDataElement: operation=DataServices_AME_Read_AME_diagnostic_version_FD08_CombinedDataElement.ReadDataLength
            OpServerCallDcm_MainFunction_ConditionCheckRead_DataServices_AME_Read_AME_diagnostic_version_FD08_CombinedDataElement: operation=DataServices_AME_Read_AME_diagnostic_version_FD08_CombinedDataElement.ConditionCheckRead
            OpServerCallDcm_MainFunction_ReadData_DataServices_VehicleNetworkConfiguration_F1A1_VehicleNetworkConfiguration: operation=DataServices_VehicleNetworkConfiguration_F1A1_VehicleNetworkConfiguration.ReadData
            OpServerCallDcm_MainFunction_ConditionCheckRead_DataServices_VehicleNetworkConfiguration_F1A1_VehicleNetworkConfiguration: operation=DataServices_VehicleNetworkConfiguration_F1A1_VehicleNetworkConfiguration.ConditionCheckRead
            OpServerCallDcm_MainFunction_WriteData_DataServices_VehicleNetworkConfiguration_F1A1_VehicleNetworkConfiguration: operation=DataServices_VehicleNetworkConfiguration_F1A1_VehicleNetworkConfiguration.WriteData
            OpServerCallDcm_MainFunction_ReadData_DataServices_Engine_Speed_D002_Engine_Speed: operation=DataServices_Engine_Speed_D002_Engine_Speed.ReadData
            OpServerCallDcm_MainFunction_ConditionCheckRead_DataServices_Engine_Speed_D002_Engine_Speed: operation=DataServices_Engine_Speed_D002_Engine_Speed.ConditionCheckRead
            OpServerCallDcm_MainFunction_ReadData_DataServices_Screen_resolution_E002_Height: operation=DataServices_Screen_resolution_E002_Height.ReadData
            OpServerCallDcm_MainFunction_ConditionCheckRead_DataServices_Screen_resolution_E002_Height: operation=DataServices_Screen_resolution_E002_Height.ConditionCheckRead
            OpServerCallDcm_MainFunction_ReadData_DataServices_Screen_resolution_E002_Width: operation=DataServices_Screen_resolution_E002_Width.ReadData
            OpServerCallDcm_MainFunction_ConditionCheckRead_DataServices_Screen_resolution_E002_Width: operation=DataServices_Screen_resolution_E002_Width.ConditionCheckRead
            OpServerCallDcm_MainFunction_ReadData_DataServices_AME_Read_system_voltage_FD14_CombinedDataElement: operation=DataServices_AME_Read_system_voltage_FD14_CombinedDataElement.ReadData
            OpServerCallDcm_MainFunction_ConditionCheckRead_DataServices_AME_Read_system_voltage_FD14_CombinedDataElement: operation=DataServices_AME_Read_system_voltage_FD14_CombinedDataElement.ConditionCheckRead
            OpServerCallDcm_MainFunction_ReadData_DataServices_Tbox_IP_Address_E016_Tbox_IP_Address: operation=DataServices_Tbox_IP_Address_E016_Tbox_IP_Address.ReadData
            OpServerCallDcm_MainFunction_ConditionCheckRead_DataServices_Tbox_IP_Address_E016_Tbox_IP_Address: operation=DataServices_Tbox_IP_Address_E016_Tbox_IP_Address.ConditionCheckRead
            OpServerCallDcm_MainFunction_ReadData_DataServices_DTC_Occurrence_Timer_D005_Occure_Time_Inforamation: operation=DataServices_DTC_Occurrence_Timer_D005_Occure_Time_Inforamation.ReadData
            OpServerCallDcm_MainFunction_ConditionCheckRead_DataServices_DTC_Occurrence_Timer_D005_Occure_Time_Inforamation: operation=DataServices_DTC_Occurrence_Timer_D005_Occure_Time_Inforamation.ConditionCheckRead
            OpServerCallDcm_MainFunction_WriteData_DataServices_INVALID_SHORTNAME_AME_Reset_Factory_Mode_FD05_Reset_Factory_Mode: operation=DataServices_INVALID_SHORTNAME_AME_Reset_Factory_Mode_FD05_Reset_Factory_Mode.WriteData
            OpServerCallDcm_MainFunction_ReadData_DataServices_Tbox_geographical_coordinates_when_connection_lost_E019_Tbox_geograp_bc80f26f: operation=DataServices_Tbox_geographical_coordinates_when_connection_lost_E019_Tbox_geographical_coordinates_when_connection_lost.ReadData
            OpServerCallDcm_MainFunction_ConditionCheckRead_DataServices_Tbox_geographical_coordinates_when_connection_lost_E019_Tb_b11e7994: operation=DataServices_Tbox_geographical_coordinates_when_connection_lost_E019_Tbox_geographical_coordinates_when_connection_lost.ConditionCheckRead
            OpServerCallDcm_MainFunction_ReadData_DataServices_AME_Read_GYRO_Status_FD71_GYRO_Status: operation=DataServices_AME_Read_GYRO_Status_FD71_GYRO_Status.ReadData
            OpServerCallDcm_MainFunction_ConditionCheckRead_DataServices_AME_Read_GYRO_Status_FD71_GYRO_Status: operation=DataServices_AME_Read_GYRO_Status_FD71_GYRO_Status.ConditionCheckRead
            OpServerCallDcm_MainFunction_ReadData_DataServices_Wi_Fi_Module_Firmware_Version_E014_Wi_Fi_Module_Firmware_Version: operation=DataServices_Wi_Fi_Module_Firmware_Version_E014_Wi_Fi_Module_Firmware_Version.ReadData
            OpServerCallDcm_MainFunction_ConditionCheckRead_DataServices_Wi_Fi_Module_Firmware_Version_E014_Wi_Fi_Module_Firmware_Version: operation=DataServices_Wi_Fi_Module_Firmware_Version_E014_Wi_Fi_Module_Firmware_Version.ConditionCheckRead
            OpServerCallDcm_MainFunction_WriteData_DataServices_AME_Select_Speaker_Zone_FD33_Select_Speaker_Zone: operation=DataServices_AME_Select_Speaker_Zone_FD33_Select_Speaker_Zone.WriteData
            OpServerCallDcm_MainFunction_WriteData_DataServices_AME_Play_BT_Audio_Control_FD64_Reserved_Byte: operation=DataServices_AME_Play_BT_Audio_Control_FD64_Reserved_Byte.WriteData
            OpServerCallDcm_MainFunction_WriteData_DataServices_AME_Switch_BIOS_Mode_FD02_Switch_BIOS: operation=DataServices_AME_Switch_BIOS_Mode_FD02_Switch_BIOS.WriteData
            OpServerCallDcm_MainFunction_WriteData_DataServices_AME_Ethernet_IP_Ping_Function_FD6E_IPAddress_Byte3: operation=DataServices_AME_Ethernet_IP_Ping_Function_FD6E_IPAddress_Byte3.WriteData
            OpServerCallDcm_MainFunction_WriteData_DataServices_AME_Ethernet_IP_Ping_Function_FD6E_IPAddress_Byte4: operation=DataServices_AME_Ethernet_IP_Ping_Function_FD6E_IPAddress_Byte4.WriteData
            OpServerCallDcm_MainFunction_WriteData_DataServices_AME_Ethernet_IP_Ping_Function_FD6E_Ethernet_Channel: operation=DataServices_AME_Ethernet_IP_Ping_Function_FD6E_Ethernet_Channel.WriteData
            OpServerCallDcm_MainFunction_WriteData_DataServices_AME_Ethernet_IP_Ping_Function_FD6E_IPAddress_Byte1: operation=DataServices_AME_Ethernet_IP_Ping_Function_FD6E_IPAddress_Byte1.WriteData
            OpServerCallDcm_MainFunction_WriteData_DataServices_AME_Ethernet_IP_Ping_Function_FD6E_IPAddress_Byte2: operation=DataServices_AME_Ethernet_IP_Ping_Function_FD6E_IPAddress_Byte2.WriteData
            OpServerCallDcm_MainFunction_ReadData_DataServices_AM_signal_Strength_E011_AM_signal_Strength: operation=DataServices_AM_signal_Strength_E011_AM_signal_Strength.ReadData
            OpServerCallDcm_MainFunction_ConditionCheckRead_DataServices_AM_signal_Strength_E011_AM_signal_Strength: operation=DataServices_AM_signal_Strength_E011_AM_signal_Strength.ConditionCheckRead
            OpServerCallDcm_MainFunction_ReadData_DataServices_Tbox_Last_connection_lost_time_stamp_E018_Tbox_Last_connection_lost_54f9a3f3: operation=DataServices_Tbox_Last_connection_lost_time_stamp_E018_Tbox_Last_connection_lost_time_stamp.ReadData
            OpServerCallDcm_MainFunction_ConditionCheckRead_DataServices_Tbox_Last_connection_lost_time_stamp_E018_Tbox_Last_connec_1ec03419: operation=DataServices_Tbox_Last_connection_lost_time_stamp_E018_Tbox_Last_connection_lost_time_stamp.ConditionCheckRead
            OpServerCallDcm_MainFunction_ReadData_DataServices_AME_Read_Detection_Input_Info_FD92_CombinedDataElement: operation=DataServices_AME_Read_Detection_Input_Info_FD92_CombinedDataElement.ReadData
            OpServerCallDcm_MainFunction_ConditionCheckRead_DataServices_AME_Read_Detection_Input_Info_FD92_CombinedDataElement: operation=DataServices_AME_Read_Detection_Input_Info_FD92_CombinedDataElement.ConditionCheckRead
            OpServerCallDcm_MainFunction_ReadData_DataServices_Data_DID_StartApplication: operation=DataServices_Data_DID_StartApplication.ReadData
            OpServerCallDcm_MainFunction_ConditionCheckRead_DataServices_Data_DID_StartApplication: operation=DataServices_Data_DID_StartApplication.ConditionCheckRead
            OpServerCallDcm_MainFunction_WriteData_DataServices_Data_DID_StartApplication: operation=DataServices_Data_DID_StartApplication.WriteData
        GetActiveProtocol: can-be-invoked-concurrently=true, symbol=Dcm_GetActiveProtocol
        GetSesCtrlType: can-be-invoked-concurrently=true, symbol=Dcm_GetSesCtrlType
        ResetToDefaultSession: can-be-invoked-concurrently=true, symbol=Dcm_ResetToDefaultSession
        GetSecurityLevel: can-be-invoked-concurrently=true, symbol=Dcm_GetSecurityLevel
        SetActiveDiagnostic: can-be-invoked-concurrently=true, symbol=Dcm_SetActiveDiagnostic
        GetRequestKind: can-be-invoked-concurrently=true, symbol=Dcm_GetRequestKind
  swc implementation DcmImplementation: programming-language=C, behavior=DcmInternalBehavior
